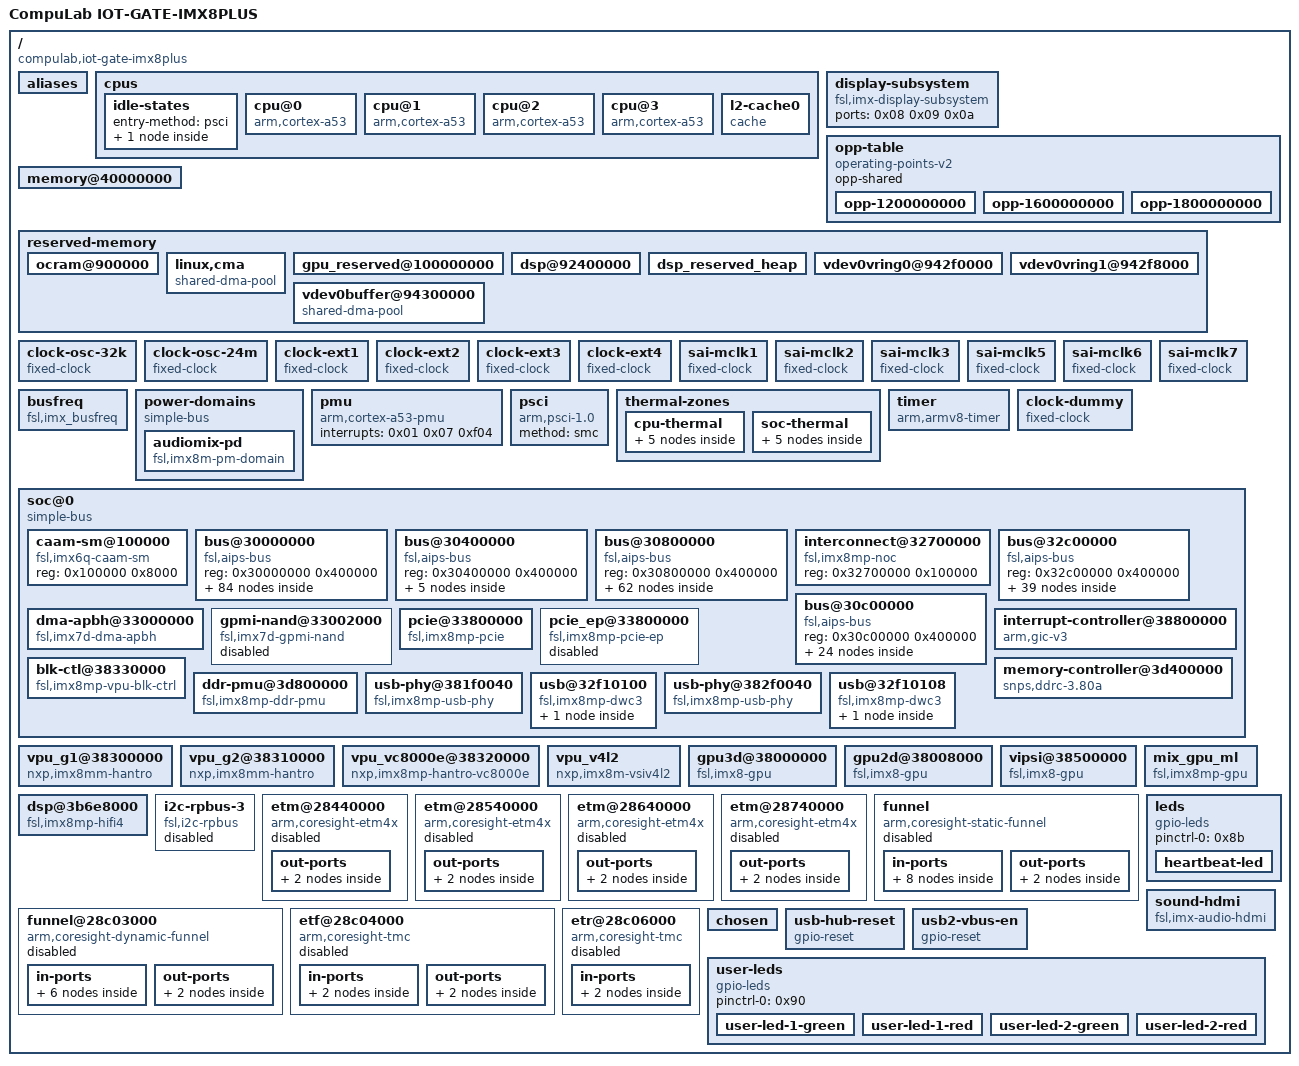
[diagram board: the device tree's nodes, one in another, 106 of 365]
/*
 * Copyright Linux Kernel Team
 *
 * SPDX-License-Identifier: GPL-2.0-only
 *
 * This file is derived from an intermediate build stage of the
 * Linux kernel. The licenses of all input files to this process
 * are compatible with GPL-2.0-only.
 */
/dts-v1/;

/ {
	interrupt-parent = <0x01>;
	#address-cells = <0x02>;
	#size-cells = <0x02>;
	model = "CompuLab IOT-GATE-IMX8PLUS";
	compatible = "compulab,iot-gate-imx8plus", "compulab,ucm-imx8m-plus-som", "fsl,imx8mp";

	aliases {
		ethernet0 = "/soc@0/bus@30800000/ethernet@30be0000";
		ethernet1 = "/soc@0/bus@30800000/ethernet@30bf0000";
		gpio0 = "/soc@0/bus@30000000/gpio@30200000";
		gpio1 = "/soc@0/bus@30000000/gpio@30210000";
		gpio2 = "/soc@0/bus@30000000/gpio@30220000";
		gpio3 = "/soc@0/bus@30000000/gpio@30230000";
		gpio4 = "/soc@0/bus@30000000/gpio@30240000";
		i2c0 = "/soc@0/bus@30800000/i2c@30a20000";
		i2c1 = "/soc@0/bus@30800000/i2c@30a30000";
		i2c2 = "/soc@0/bus@30800000/i2c@30a40000";
		i2c3 = "/soc@0/bus@30800000/i2c@30a50000";
		i2c4 = "/soc@0/bus@30800000/i2c@30ad0000";
		i2c5 = "/soc@0/bus@30800000/i2c@30ae0000";
		mmc0 = "/soc@0/bus@30800000/mmc@30b40000";
		mmc1 = "/soc@0/bus@30800000/mmc@30b50000";
		mmc2 = "/soc@0/bus@30800000/mmc@30b60000";
		serial0 = "/soc@0/bus@30800000/serial@30860000";
		serial1 = "/soc@0/bus@30800000/serial@30890000";
		serial2 = "/soc@0/bus@30800000/serial@30880000";
		serial3 = "/soc@0/bus@30800000/serial@30a60000";
		spi0 = "/soc@0/bus@30800000/spi@30bb0000";
		isi0 = "/soc@0/bus@32c00000/camera/isi@32e00000";
		isi1 = "/soc@0/bus@32c00000/camera/isi@32e02000";
		csi0 = "/soc@0/bus@32c00000/camera/csi@32e40000";
		csi1 = "/soc@0/bus@32c00000/camera/csi@32e50000";
		isp0 = "/soc@0/bus@32c00000/camera/isp@32e10000";
		isp1 = "/soc@0/bus@32c00000/camera/isp@32e20000";
		rtc0 = "/soc@0/bus@30800000/i2c@30a30000/rtc@69";
		rtc1 = "/soc@0/bus@30000000/snvs@30370000/snvs-rtc-lp";
	};

	cpus {
		#address-cells = <0x01>;
		#size-cells = <0x00>;

		idle-states {
			entry-method = "psci";

			cpu-pd-wait {
				compatible = "arm,idle-state";
				arm,psci-suspend-param = <0x10033>;
				local-timer-stop;
				entry-latency-us = <0x3e8>;
				exit-latency-us = <0x2bc>;
				min-residency-us = <0xa8c>;
				wakeup-latency-us = <0x5dc>;
				phandle = <0x06>;
			};
		};

		cpu@0 {
			device_type = "cpu";
			compatible = "arm,cortex-a53";
			reg = <0x00>;
			clock-latency = <0xee6c>;
			clocks = <0x02 0x11f>;
			enable-method = "psci";
			i-cache-size = <0x8000>;
			i-cache-line-size = <0x40>;
			i-cache-sets = <0x100>;
			d-cache-size = <0x8000>;
			d-cache-line-size = <0x40>;
			d-cache-sets = <0x80>;
			next-level-cache = <0x03>;
			nvmem-cells = <0x04>;
			nvmem-cell-names = "speed_grade";
			operating-points-v2 = <0x05>;
			#cooling-cells = <0x02>;
			cpu-idle-states = <0x06>;
			cpu-supply = <0x07>;
			phandle = <0x0d>;
		};

		cpu@1 {
			device_type = "cpu";
			compatible = "arm,cortex-a53";
			reg = <0x01>;
			clock-latency = <0xee6c>;
			clocks = <0x02 0x11f>;
			enable-method = "psci";
			i-cache-size = <0x8000>;
			i-cache-line-size = <0x40>;
			i-cache-sets = <0x100>;
			d-cache-size = <0x8000>;
			d-cache-line-size = <0x40>;
			d-cache-sets = <0x80>;
			next-level-cache = <0x03>;
			operating-points-v2 = <0x05>;
			#cooling-cells = <0x02>;
			cpu-idle-states = <0x06>;
			cpu-supply = <0x07>;
			phandle = <0x0e>;
		};

		cpu@2 {
			device_type = "cpu";
			compatible = "arm,cortex-a53";
			reg = <0x02>;
			clock-latency = <0xee6c>;
			clocks = <0x02 0x11f>;
			enable-method = "psci";
			i-cache-size = <0x8000>;
			i-cache-line-size = <0x40>;
			i-cache-sets = <0x100>;
			d-cache-size = <0x8000>;
			d-cache-line-size = <0x40>;
			d-cache-sets = <0x80>;
			next-level-cache = <0x03>;
			operating-points-v2 = <0x05>;
			#cooling-cells = <0x02>;
			cpu-idle-states = <0x06>;
			cpu-supply = <0x07>;
			phandle = <0x0f>;
		};

		cpu@3 {
			device_type = "cpu";
			compatible = "arm,cortex-a53";
			reg = <0x03>;
			clock-latency = <0xee6c>;
			clocks = <0x02 0x11f>;
			enable-method = "psci";
			i-cache-size = <0x8000>;
			i-cache-line-size = <0x40>;
			i-cache-sets = <0x100>;
			d-cache-size = <0x8000>;
			d-cache-line-size = <0x40>;
			d-cache-sets = <0x80>;
			next-level-cache = <0x03>;
			operating-points-v2 = <0x05>;
			#cooling-cells = <0x02>;
			cpu-idle-states = <0x06>;
			cpu-supply = <0x07>;
			phandle = <0x10>;
		};

		l2-cache0 {
			compatible = "cache";
			cache-level = <0x02>;
			cache-size = <0x80000>;
			cache-line-size = <0x40>;
			cache-sets = <0x200>;
			phandle = <0x03>;
		};
	};

	display-subsystem {
		compatible = "fsl,imx-display-subsystem";
		ports = <0x08 0x09 0x0a>;
	};

	opp-table {
		compatible = "operating-points-v2";
		opp-shared;
		phandle = <0x05>;

		opp-1200000000 {
			opp-hz = <0x00 0x47868c00>;
			opp-microvolt = <0xcf850>;
			opp-supported-hw = <0x8a0 0x07>;
			clock-latency-ns = <0x249f0>;
			opp-suspend;
		};

		opp-1600000000 {
			opp-hz = <0x00 0x5f5e1000>;
			opp-microvolt = <0xe7ef0>;
			opp-supported-hw = <0xa0 0x07>;
			clock-latency-ns = <0x249f0>;
			opp-suspend;
		};

		opp-1800000000 {
			opp-hz = <0x00 0x6b49d200>;
			opp-microvolt = <0xf4240>;
			opp-supported-hw = <0x20 0x03>;
			clock-latency-ns = <0x249f0>;
			opp-suspend;
		};
	};

	memory@40000000 {
		device_type = "memory";
		reg = <0x00 0x40000000 0x00 0xc0000000 0x01 0x00 0x00 0xc0000000>;
	};

	reserved-memory {
		#address-cells = <0x02>;
		#size-cells = <0x02>;
		ranges;
		phandle = <0x91>;

		ocram@900000 {
			no-map;
			reg = <0x00 0x900000 0x00 0x70000>;
			phandle = <0x92>;
		};

		linux,cma {
			compatible = "shared-dma-pool";
			reusable;
			size = <0x00 0x2c000000>;
			alloc-ranges = <0x00 0x40000000 0x00 0x80000000>;
			linux,cma-default;
		};

		gpu_reserved@100000000 {
			no-map;
			reg = <0x00 0x58000000 0x00 0x10000000>;
			phandle = <0x77>;
		};

		dsp@92400000 {
			reg = <0x00 0x92400000 0x00 0x1000000>;
			no-map;
			phandle = <0x7c>;
		};

		dsp_reserved_heap {
			reg = <0x00 0x93400000 0x00 0xef0000>;
			no-map;
			phandle = <0x93>;
		};

		vdev0vring0@942f0000 {
			reg = <0x00 0x942f0000 0x00 0x8000>;
			no-map;
			phandle = <0x7a>;
		};

		vdev0vring1@942f8000 {
			reg = <0x00 0x942f8000 0x00 0x8000>;
			no-map;
			phandle = <0x7b>;
		};

		vdev0buffer@94300000 {
			compatible = "shared-dma-pool";
			reg = <0x00 0x94300000 0x00 0x100000>;
			no-map;
			phandle = <0x79>;
		};
	};

	clock-osc-32k {
		compatible = "fixed-clock";
		#clock-cells = <0x00>;
		clock-frequency = <0x8000>;
		clock-output-names = "osc_32k";
		phandle = <0x17>;
	};

	clock-osc-24m {
		compatible = "fixed-clock";
		#clock-cells = <0x00>;
		clock-frequency = <0x16e3600>;
		clock-output-names = "osc_24m";
		phandle = <0x18>;
	};

	clock-ext1 {
		compatible = "fixed-clock";
		#clock-cells = <0x00>;
		clock-frequency = <0x7ed6b40>;
		clock-output-names = "clk_ext1";
		phandle = <0x19>;
	};

	clock-ext2 {
		compatible = "fixed-clock";
		#clock-cells = <0x00>;
		clock-frequency = <0x7ed6b40>;
		clock-output-names = "clk_ext2";
		phandle = <0x1a>;
	};

	clock-ext3 {
		compatible = "fixed-clock";
		#clock-cells = <0x00>;
		clock-frequency = <0x7ed6b40>;
		clock-output-names = "clk_ext3";
		phandle = <0x1b>;
	};

	clock-ext4 {
		compatible = "fixed-clock";
		#clock-cells = <0x00>;
		clock-frequency = <0x7ed6b40>;
		clock-output-names = "clk_ext4";
		phandle = <0x1c>;
	};

	sai-mclk1 {
		compatible = "fixed-clock";
		#clock-cells = <0x00>;
		clock-frequency = <0x00>;
		clock-output-names = "sai1_mclk";
		phandle = <0x94>;
	};

	sai-mclk2 {
		compatible = "fixed-clock";
		#clock-cells = <0x00>;
		clock-frequency = <0x00>;
		clock-output-names = "sai2_mclk";
		phandle = <0x95>;
	};

	sai-mclk3 {
		compatible = "fixed-clock";
		#clock-cells = <0x00>;
		clock-frequency = <0x00>;
		clock-output-names = "sai3_mclk";
		phandle = <0x96>;
	};

	sai-mclk5 {
		compatible = "fixed-clock";
		#clock-cells = <0x00>;
		clock-frequency = <0x00>;
		clock-output-names = "sai5_mclk";
		phandle = <0x97>;
	};

	sai-mclk6 {
		compatible = "fixed-clock";
		#clock-cells = <0x00>;
		clock-frequency = <0x00>;
		clock-output-names = "sai6_mclk";
		phandle = <0x98>;
	};

	sai-mclk7 {
		compatible = "fixed-clock";
		#clock-cells = <0x00>;
		clock-frequency = <0x00>;
		clock-output-names = "sai7_mclk";
		phandle = <0x99>;
	};

	busfreq {
		compatible = "fsl,imx_busfreq";
		clocks = <0x02 0x29 0x02 0x70 0x02 0x71 0x02 0x71 0x02 0x11e 0x02 0x11d 0x02 0x30 0x02 0x32 0x02 0x3f 0x02 0x67 0x02 0x6b 0x02 0x5d 0x02 0x02 0x02 0x38 0x02 0x15>;
		clock-names = "dram_pll", "dram_alt_src", "dram_apb_src", "dram_apb_pre_div", "dram_core", "dram_alt_root", "sys_pll1_40m", "sys_pll1_100m", "sys_pll2_333m", "noc_div", "ahb_div", "main_axi_src", "osc_24m", "sys_pll1_800m", "dram_pll_div";
	};

	power-domains {
		compatible = "simple-bus";

		audiomix-pd {
			compatible = "fsl,imx8m-pm-domain";
			#power-domain-cells = <0x00>;
			domain-index = <0x05>;
			domain-name = "audiomix";
			clocks = <0x02 0x141 0x02 0x142>;
			phandle = <0x60>;
		};
	};

	pmu {
		compatible = "arm,cortex-a53-pmu";
		interrupts = <0x01 0x07 0xf04>;
	};

	psci {
		compatible = "arm,psci-1.0";
		method = "smc";
	};

	thermal-zones {

		cpu-thermal {
			polling-delay-passive = <0xfa>;
			polling-delay = <0x7d0>;
			thermal-sensors = <0x0b 0x00>;

			trips {

				trip0 {
					temperature = <0x186a0>;
					hysteresis = <0x7d0>;
					type = "passive";
					phandle = <0x0c>;
				};

				trip1 {
					temperature = <0x19a28>;
					hysteresis = <0x7d0>;
					type = "critical";
					phandle = <0x9a>;
				};
			};

			cooling-maps {

				map0 {
					trip = <0x0c>;
					cooling-device = <0x0d 0xffffffff 0xffffffff 0x0e 0xffffffff 0xffffffff 0x0f 0xffffffff 0xffffffff 0x10 0xffffffff 0xffffffff>;
				};
			};
		};

		soc-thermal {
			polling-delay-passive = <0xfa>;
			polling-delay = <0x7d0>;
			thermal-sensors = <0x0b 0x01>;

			trips {

				trip0 {
					temperature = <0x186a0>;
					hysteresis = <0x7d0>;
					type = "passive";
					phandle = <0x11>;
				};

				trip1 {
					temperature = <0x19a28>;
					hysteresis = <0x7d0>;
					type = "critical";
					phandle = <0x9b>;
				};
			};

			cooling-maps {

				map0 {
					trip = <0x11>;
					cooling-device = <0x0d 0xffffffff 0xffffffff 0x0e 0xffffffff 0xffffffff 0x0f 0xffffffff 0xffffffff 0x10 0xffffffff 0xffffffff>;
				};
			};
		};
	};

	timer {
		compatible = "arm,armv8-timer";
		interrupts = <0x01 0x0d 0xf08 0x01 0x0e 0xf08 0x01 0x0b 0xf08 0x01 0x0a 0xf08>;
		clock-frequency = <0x7a1200>;
		arm,no-tick-in-suspend;
		interrupt-parent = <0x01>;
	};

	clock-dummy {
		compatible = "fixed-clock";
		#clock-cells = <0x00>;
		clock-frequency = <0x00>;
		clock-output-names = "clk_dummy";
		phandle = <0x9c>;
	};

	soc@0 {
		compatible = "simple-bus";
		#address-cells = <0x01>;
		#size-cells = <0x01>;
		ranges = <0x00 0x00 0x00 0x3e000000>;
		nvmem-cells = <0x12>;
		nvmem-cell-names = "soc_unique_id";
		phandle = <0x9d>;

		caam-sm@100000 {
			compatible = "fsl,imx6q-caam-sm";
			reg = <0x100000 0x8000>;
			phandle = <0x9e>;
		};

		bus@30000000 {
			compatible = "fsl,aips-bus", "simple-bus";
			reg = <0x30000000 0x400000>;
			#address-cells = <0x01>;
			#size-cells = <0x01>;
			ranges;
			phandle = <0x9f>;

			gpio@30200000 {
				compatible = "fsl,imx8mp-gpio", "fsl,imx35-gpio";
				reg = <0x30200000 0x10000>;
				interrupts = <0x00 0x40 0x04 0x00 0x41 0x04>;
				clocks = <0x02 0xc1>;
				gpio-controller;
				#gpio-cells = <0x02>;
				interrupt-controller;
				#interrupt-cells = <0x02>;
				gpio-ranges = <0x13 0x00 0x05 0x1e>;
				gpio-line-names = "", "", "", "PMIC IRQ", "", "", "", "", "", "", "ECOS PHY Reset", "", "Heartbeat LED", "", "", "USB MUX Sel", "", "", "", "", "", "", "", "", "", "", "", "", "", "";
				status = "okay";
				phandle = <0x2b>;
			};

			gpio@30210000 {
				compatible = "fsl,imx8mp-gpio", "fsl,imx35-gpio";
				reg = <0x30210000 0x10000>;
				interrupts = <0x00 0x42 0x04 0x00 0x43 0x04>;
				clocks = <0x02 0xc2>;
				gpio-controller;
				#gpio-cells = <0x02>;
				interrupt-controller;
				#interrupt-cells = <0x02>;
				gpio-ranges = <0x13 0x00 0x23 0x15>;
				phandle = <0x8e>;
			};

			gpio@30220000 {
				compatible = "fsl,imx8mp-gpio", "fsl,imx35-gpio";
				reg = <0x30220000 0x10000>;
				interrupts = <0x00 0x44 0x04 0x00 0x45 0x04>;
				clocks = <0x02 0xc3>;
				gpio-controller;
				#gpio-cells = <0x02>;
				interrupt-controller;
				#interrupt-cells = <0x02>;
				gpio-ranges = <0x13 0x00 0x38 0x1a 0x13 0x1a 0x90 0x04>;
				phandle = <0xa0>;
			};

			gpio@30230000 {
				compatible = "fsl,imx8mp-gpio", "fsl,imx35-gpio";
				reg = <0x30230000 0x10000>;
				interrupts = <0x00 0x46 0x04 0x00 0x47 0x04>;
				clocks = <0x02 0xc4>;
				gpio-controller;
				#gpio-cells = <0x02>;
				interrupt-controller;
				#interrupt-cells = <0x02>;
				gpio-ranges = <0x13 0x00 0x52 0x20>;
				phandle = <0x40>;
			};

			gpio@30240000 {
				compatible = "fsl,imx8mp-gpio", "fsl,imx35-gpio";
				reg = <0x30240000 0x10000>;
				interrupts = <0x00 0x48 0x04 0x00 0x49 0x04>;
				clocks = <0x02 0xc5>;
				gpio-controller;
				#gpio-cells = <0x02>;
				interrupt-controller;
				#interrupt-cells = <0x02>;
				gpio-ranges = <0x13 0x00 0x72 0x1e>;
				phandle = <0x22>;
			};

			tmu@30260000 {
				compatible = "fsl,imx8mp-tmu";
				reg = <0x30260000 0x10000>;
				clocks = <0x02 0x119>;
				#thermal-sensor-cells = <0x01>;
				phandle = <0x0b>;
			};

			watchdog@30280000 {
				compatible = "fsl,imx8mp-wdt", "fsl,imx21-wdt";
				reg = <0x30280000 0x10000>;
				interrupts = <0x00 0x4e 0x04>;
				clocks = <0x02 0x103>;
				status = "okay";
				pinctrl-names = "default";
				pinctrl-0 = <0x14>;
				fsl,ext-reset-output;
				phandle = <0xa1>;
			};

			watchdog@30290000 {
				compatible = "fsl,imx8mp-wdt", "fsl,imx21-wdt";
				reg = <0x30290000 0x10000>;
				interrupts = <0x00 0x4f 0x04>;
				clocks = <0x02 0x104>;
				status = "disabled";
				phandle = <0xa2>;
			};

			watchdog@302a0000 {
				compatible = "fsl,imx8mp-wdt", "fsl,imx21-wdt";
				reg = <0x302a0000 0x10000>;
				interrupts = <0x00 0x0a 0x04>;
				clocks = <0x02 0x105>;
				status = "disabled";
				phandle = <0xa3>;
			};

			pinctrl@30330000 {
				compatible = "fsl,imx8mp-iomuxc";
				reg = <0x30330000 0x10000>;
				pinctrl-names = "default";
				pinctrl-0 = <0x15>;
				phandle = <0x13>;

				fecgrp {
					fsl,pins = <0x8c 0x2ec 0x00 0x01 0x00 0x03 0x90 0x2f0 0x57c 0x01 0x00 0x03 0x9c 0x2fc 0x580 0x01 0x00 0x91 0xa0 0x300 0x584 0x01 0x00 0x91 0x168 0x3c8 0x00 0x04 0x00 0x91 0x16c 0x3cc 0x00 0x04 0x00 0x91 0x174 0x3d4 0x00 0x04 0x00 0x91 0x170 0x3d0 0x588 0x04 0x01 0x91 0x98 0x2f8 0x00 0x01 0x00 0x1f 0x94 0x2f4 0x00 0x01 0x00 0x1f 0x180 0x3e0 0x00 0x04 0x00 0x1f 0x184 0x3e4 0x00 0x04 0x00 0x1f 0x188 0x3e8 0x00 0x04 0x00 0x1f 0x18c 0x3ec 0x00 0x04 0x00 0x1f>;
					phandle = <0x3d>;
				};

				ecspi2grp {
					fsl,pins = <0x1f0 0x450 0x568 0x00 0x01 0x82 0x1f4 0x454 0x570 0x00 0x01 0x82 0x1f8 0x458 0x56c 0x00 0x01 0x82>;
					phandle = <0x20>;
				};

				ecspi2cs {
					fsl,pins = <0x1fc 0x45c 0x00 0x05 0x00 0x40000>;
					phandle = <0x21>;
				};

				eqosgrp {
					fsl,pins = <0x54 0x2b4 0x00 0x00 0x00 0x03 0x58 0x2b8 0x590 0x00 0x01 0x03 0x7c 0x2dc 0x00 0x00 0x00 0x91 0x80 0x2e0 0x00 0x00 0x00 0x91 0x84 0x2e4 0x00 0x00 0x00 0x91 0x88 0x2e8 0x00 0x00 0x00 0x91 0x78 0x2d8 0x00 0x00 0x00 0x91 0x74 0x2d4 0x00 0x00 0x00 0x91 0x68 0x2c8 0x00 0x00 0x00 0x1f 0x64 0x2c4 0x00 0x00 0x00 0x1f 0x60 0x2c0 0x00 0x00 0x00 0x1f 0x5c 0x2bc 0x00 0x00 0x00 0x1f 0x6c 0x2cc 0x00 0x00 0x00 0x1f 0x70 0x2d0 0x00 0x00 0x00 0x1f>;
					phandle = <0x42>;
				};

				ecosphyrstgrp {
					fsl,pins = <0x3c 0x29c 0x00 0x00 0x00 0x19>;
					phandle = <0x43>;
				};

				flexspi0grp {
					fsl,pins = <0xe0 0x340 0x00 0x01 0x00 0x1c2 0xe4 0x344 0x00 0x01 0x00 0x82 0xf8 0x358 0x00 0x01 0x00 0x82 0xfc 0x35c 0x00 0x01 0x00 0x82 0x100 0x360 0x00 0x01 0x00 0x82 0x104 0x364 0x00 0x01 0x00 0x82>;
					phandle = <0x3b>;
				};

				gpioledgrp {
					fsl,pins = <0x120 0x380 0x00 0x05 0x00 0x19>;
					phandle = <0x8b>;
				};

				i2c1grp {
					fsl,pins = <0x200 0x460 0x5a4 0x00 0x02 0x400001c3 0x204 0x464 0x5a8 0x00 0x02 0x400001c3>;
					phandle = <0x29>;
				};

				i2c2grp {
					fsl,pins = <0x208 0x468 0x5ac 0x00 0x02 0x400001c3 0x20c 0x46c 0x5b0 0x00 0x02 0x400001c3>;
					phandle = <0x2c>;
				};

				i2c3grp {
					fsl,pins = <0x210 0x470 0x5b4 0x00 0x04 0x400001c3 0x214 0x474 0x5b8 0x00 0x04 0x400001c3>;
					phandle = <0x2d>;
				};

				i2c5grp {
					fsl,pins = <0x144 0x3a4 0x5c8 0x03 0x01 0x400001c3 0x134 0x394 0x5c4 0x03 0x01 0x400001c3>;
					phandle = <0x30>;
				};

				i2c6grp {
					fsl,pins = <0x12c 0x38c 0x5cc 0x03 0x01 0x400001c3 0x130 0x390 0x5d0 0x03 0x01 0x400001c3>;
					phandle = <0x31>;
				};

				pmicirq {
					fsl,pins = <0x20 0x280 0x00 0x00 0x00 0x41>;
					phandle = <0x2a>;
				};

				pdmgrp {
					fsl,pins = <0x130 0x390 0x00 0x04 0x00 0xd6 0x134 0x394 0x4c0 0x04 0x03 0xd6 0x138 0x398 0x4c4 0x04 0x03 0xd6 0x13c 0x39c 0x4c8 0x04 0x03 0xd6 0x140 0x3a0 0x4cc 0x04 0x03 0xd6>;
					phandle = <0xa4>;
				};

				uart1grp {
					fsl,pins = <0x220 0x480 0x5e8 0x00 0x04 0x140 0x224 0x484 0x00 0x00 0x00 0x140>;
					phandle = <0x23>;
				};

				uart2grp {
					fsl,pins = <0x228 0x488 0x5f0 0x00 0x06 0x140 0x22c 0x48c 0x00 0x00 0x00 0x140>;
					phandle = <0x25>;
				};

				uart3grp {
					fsl,pins = <0x230 0x490 0x5f8 0x00 0x06 0x140 0x234 0x494 0x00 0x00 0x00 0x140>;
					phandle = <0x24>;
				};

				uart4grp {
					fsl,pins = <0x23c 0x49c 0x00 0x00 0x00 0x140 0x238 0x498 0x600 0x00 0x08 0x140>;
					phandle = <0x2e>;
				};

				usdhc1grp {
					fsl,pins = <0x8c 0x2ec 0x00 0x00 0x00 0x190 0x90 0x2f0 0x00 0x00 0x00 0x1d0 0x94 0x2f4 0x00 0x00 0x00 0x1d0 0x98 0x2f8 0x00 0x00 0x00 0x1d0 0x9c 0x2fc 0x00 0x00 0x00 0x1d0 0xa0 0x300 0x00 0x00 0x00 0x1d0>;
					phandle = <0x32>;
				};

				usdhc1grp-100mhz {
					fsl,pins = <0x8c 0x2ec 0x00 0x00 0x00 0x194 0x90 0x2f0 0x00 0x00 0x00 0x1d4 0x94 0x2f4 0x00 0x00 0x00 0x1d4 0x98 0x2f8 0x00 0x00 0x00 0x1d4 0x9c 0x2fc 0x00 0x00 0x00 0x1d4 0xa0 0x300 0x00 0x00 0x00 0x1d4>;
					phandle = <0x33>;
				};

				usdhc1grp-200mhz {
					fsl,pins = <0x8c 0x2ec 0x00 0x00 0x00 0x196 0x90 0x2f0 0x00 0x00 0x00 0x1d6 0x94 0x2f4 0x00 0x00 0x00 0x1d6 0x98 0x2f8 0x00 0x00 0x00 0x1d6 0x9c 0x2fc 0x00 0x00 0x00 0x1d6 0xa0 0x300 0x00 0x00 0x00 0x1d6>;
					phandle = <0x34>;
				};

				usdhc2grp {
					fsl,pins = <0xc0 0x320 0x00 0x00 0x00 0x190 0xc4 0x324 0x00 0x00 0x00 0x1d0 0xc8 0x328 0x00 0x00 0x00 0x1d0 0xcc 0x32c 0x00 0x00 0x00 0x1d0 0xd0 0x330 0x00 0x00 0x00 0x1d0 0xd4 0x334 0x00 0x00 0x00 0x1d0>;
					phandle = <0x35>;
				};

				usdhc2grp-100mhz {
					fsl,pins = <0xc0 0x320 0x00 0x00 0x00 0x194 0xc4 0x324 0x00 0x00 0x00 0x1d4 0xc8 0x328 0x00 0x00 0x00 0x1d4 0xcc 0x32c 0x00 0x00 0x00 0x1d4 0xd0 0x330 0x00 0x00 0x00 0x1d4 0xd4 0x334 0x00 0x00 0x00 0x1d4>;
					phandle = <0x36>;
				};

				usdhc2grp-200mhz {
					fsl,pins = <0xc0 0x320 0x00 0x00 0x00 0x196 0xc4 0x324 0x00 0x00 0x00 0x1d6 0xc8 0x328 0x00 0x00 0x00 0x1d6 0xcc 0x32c 0x00 0x00 0x00 0x1d6 0xd0 0x330 0x00 0x00 0x00 0x1d6 0xd4 0x334 0x00 0x00 0x00 0x1d6>;
					phandle = <0x37>;
				};

				usdhc3grp {
					fsl,pins = <0x124 0x384 0x604 0x02 0x01 0x190 0x128 0x388 0x60c 0x02 0x01 0x1d0 0x108 0x368 0x610 0x02 0x01 0x1d0 0x10c 0x36c 0x614 0x02 0x01 0x1d0 0x110 0x370 0x618 0x02 0x01 0x1d0 0x114 0x374 0x61c 0x02 0x01 0x1d0 0x11c 0x37c 0x620 0x02 0x01 0x1d0 0xec 0x34c 0x624 0x02 0x01 0x1d0 0xf0 0x350 0x628 0x02 0x01 0x1d0 0xf4 0x354 0x62c 0x02 0x01 0x1d0 0xe8 0x348 0x630 0x02 0x01 0x190>;
					phandle = <0x38>;
				};

				usdhc3grp-100mhz {
					fsl,pins = <0x124 0x384 0x604 0x02 0x01 0x194 0x128 0x388 0x60c 0x02 0x01 0x1d4 0x108 0x368 0x610 0x02 0x01 0x1d4 0x10c 0x36c 0x614 0x02 0x01 0x1d4 0x110 0x370 0x618 0x02 0x01 0x1d4 0x114 0x374 0x61c 0x02 0x01 0x1d4 0x11c 0x37c 0x620 0x02 0x01 0x1d4 0xec 0x34c 0x624 0x02 0x01 0x1d4 0xf0 0x350 0x628 0x02 0x01 0x1d4 0xf4 0x354 0x62c 0x02 0x01 0x1d4 0xe8 0x348 0x630 0x02 0x01 0x194>;
					phandle = <0x39>;
				};

				usdhc3grp-200mhz {
					fsl,pins = <0x124 0x384 0x604 0x02 0x01 0x196 0x128 0x388 0x60c 0x02 0x01 0x1d6 0x108 0x368 0x610 0x02 0x01 0x1d6 0x10c 0x36c 0x614 0x02 0x01 0x1d6 0x110 0x370 0x618 0x02 0x01 0x1d6 0x114 0x374 0x61c 0x02 0x01 0x1d6 0x11c 0x37c 0x620 0x02 0x01 0x1d6 0xec 0x34c 0x624 0x02 0x01 0x1d6 0xf0 0x350 0x628 0x02 0x01 0x1d6 0xf4 0x354 0x62c 0x02 0x01 0x1d6 0xe8 0x348 0x630 0x02 0x01 0x196>;
					phandle = <0x3a>;
				};

				wdoggrp {
					fsl,pins = <0x1c 0x27c 0x00 0x01 0x00 0xc6>;
					phandle = <0x14>;
				};

				flexcan1grp {
					fsl,pins = <0x1a0 0x400 0x00 0x03 0x00 0x154 0x1ac 0x40c 0x54c 0x03 0x01 0x154>;
					phandle = <0x27>;
				};

				flexcan2grp {
					fsl,pins = <0x1b0 0x410 0x00 0x03 0x00 0x154 0x1b4 0x414 0x550 0x03 0x01 0x154>;
					phandle = <0x28>;
				};

				hdmigrp {
					fsl,pins = <0x240 0x4a0 0x00 0x00 0x00 0x400001c3 0x244 0x4a4 0x00 0x00 0x00 0x400001c3 0x24c 0x4ac 0x00 0x00 0x00 0x40000019 0x248 0x4a8 0x00 0x00 0x00 0x40000019>;
					phandle = <0x65>;
				};

				fecphyrstgrp {
					fsl,pins = <0x1a8 0x408 0x00 0x05 0x00 0x19>;
					phandle = <0x3e>;
				};

				iedi4o4grp {
					fsl,pins = <0x1d4 0x434 0x00 0x05 0x00 0x00 0x1c8 0x428 0x00 0x05 0x00 0x00 0x1c4 0x424 0x00 0x05 0x00 0x00 0x1bc 0x41c 0x00 0x05 0x00 0x00 0x1c0 0x420 0x00 0x05 0x00 0x100 0x1d8 0x438 0x00 0x05 0x00 0x100 0x18 0x278 0x00 0x00 0x00 0x100 0x178 0x3d8 0x00 0x05 0x00 0x100>;
					phandle = <0x15>;
				};

				pciegrp {
					fsl,pins = <0x1d0 0x430 0x00 0x05 0x00 0x41>;
					phandle = <0x69>;
				};

				usbhubrst {
					fsl,pins = <0xb4 0x314 0x00 0x05 0x00 0x19>;
					phandle = <0x8d>;
				};

				usbmuxselgrp {
					fsl,pins = <0x50 0x2b0 0x00 0x00 0x00 0x114>;
					phandle = <0x6f>;
				};

				usb2vbusengrp {
					fsl,pins = <0x198 0x3f8 0x00 0x05 0x00 0x154>;
					phandle = <0x8f>;
				};

				userledsgrp {
					fsl,pins = <0xbc 0x31c 0x00 0x05 0x00 0x19 0x1dc 0x43c 0x00 0x05 0x00 0x19 0x1cc 0x42c 0x00 0x05 0x00 0x19 0x1b8 0x418 0x00 0x05 0x00 0x19>;
					phandle = <0x90>;
				};
			};

			iomuxc-gpr@30340000 {
				compatible = "fsl,imx8mp-iomuxc-gpr", "syscon";
				reg = <0x30340000 0x10000>;
				phandle = <0x26>;
			};

			efuse@30350000 {
				compatible = "fsl,imx8mp-ocotp", "fsl,imx8mm-ocotp", "syscon", "simple-mfd";
				reg = <0x30350000 0x10000>;
				clocks = <0x02 0xd6>;
				#address-cells = <0x01>;
				#size-cells = <0x01>;
				phandle = <0xa5>;

				unique-id@8 {
					reg = <0x08 0x08>;
					phandle = <0x12>;
				};

				speed-grade@10 {
					reg = <0x10 0x04>;
					phandle = <0x04>;
				};

				mac-address@90 {
					reg = <0x90 0x06>;
					phandle = <0x3c>;
				};

				mac-address@96 {
					reg = <0x96 0x06>;
					phandle = <0x41>;
				};

				imx8mp-soc {
					compatible = "fsl,imx8mp-soc";
					nvmem-cells = <0x12>;
					nvmem-cell-names = "soc_unique_id";
					phandle = <0xa6>;
				};
			};

			anatop@30360000 {
				compatible = "fsl,imx8mp-anatop", "fsl,imx8mm-anatop", "syscon";
				reg = <0x30360000 0x10000>;
				phandle = <0xa7>;
			};

			caam_secvio {
				compatible = "fsl,imx6q-caam-secvio";
				interrupts = <0x00 0x14 0x04>;
				jtag-tamper = "disabled";
				watchdog-tamper = "enabled";
				internal-boot-tamper = "enabled";
				external-pin-tamper = "disabled";
				phandle = <0xa8>;
			};

			caam-snvs@30370000 {
				compatible = "fsl,imx6q-caam-snvs";
				reg = <0x30370000 0x10000>;
				clocks = <0x02 0xf9>;
				clock-names = "ipg";
				phandle = <0xa9>;
			};

			snvs@30370000 {
				compatible = "fsl,sec-v4.0-mon", "syscon", "simple-mfd";
				reg = <0x30370000 0x10000>;
				phandle = <0x16>;

				snvs-rtc-lp {
					compatible = "fsl,sec-v4.0-mon-rtc-lp";
					regmap = <0x16>;
					offset = <0x34>;
					interrupts = <0x00 0x13 0x04 0x00 0x14 0x04>;
					clocks = <0x02 0xf9>;
					clock-names = "snvs-rtc";
					phandle = <0xaa>;
				};

				snvs-powerkey {
					compatible = "fsl,sec-v4.0-pwrkey";
					regmap = <0x16>;
					interrupts = <0x00 0x04 0x04>;
					clocks = <0x02 0xf9>;
					clock-names = "snvs-pwrkey";
					linux,keycode = <0x74>;
					wakeup-source;
					status = "okay";
					phandle = <0xab>;
				};

				snvs-lpgpr {
					compatible = "fsl,imx8mp-snvs-lpgpr", "fsl,imx7d-snvs-lpgpr";
					phandle = <0xac>;
				};
			};

			clock-controller@30380000 {
				compatible = "fsl,imx8mp-ccm";
				reg = <0x30380000 0x10000>;
				#clock-cells = <0x01>;
				clocks = <0x17 0x18 0x19 0x1a 0x1b 0x1c>;
				clock-names = "osc_32k", "osc_24m", "clk_ext1", "clk_ext2", "clk_ext3", "clk_ext4";
				assigned-clocks = <0x02 0x42 0x02 0x120 0x02 0x67 0x02 0x68 0x02 0x94 0x02 0x6c 0x02 0x48 0x02 0x12 0x02 0x13 0x02 0x14>;
				assigned-clock-parents = <0x02 0x38 0x02 0x2c 0x02 0x41 0x02 0x38 0x02 0x40 0x02 0x38 0x02 0x38>;
				assigned-clock-rates = <0x00 0x00 0x3b9aca00 0x2faf0800 0x1dcd6500 0x17d78400 0x2faf0800 0x17700000 0x15888000 0x3df582e0>;
				phandle = <0x02>;
			};

			reset-controller@30390000 {
				compatible = "fsl,imx8mp-src", "syscon";
				reg = <0x30390000 0x10000>;
				interrupts = <0x00 0x59 0x04>;
				#reset-cells = <0x01>;
				phandle = <0x50>;
			};

			gpc@303a0000 {
				compatible = "fsl,imx8mp-gpc";
				reg = <0x303a0000 0x1000>;
				interrupt-parent = <0x01>;
				interrupts = <0x00 0x57 0x04>;
				interrupt-controller;
				#interrupt-cells = <0x03>;
				phandle = <0xad>;

				pgc {
					#address-cells = <0x01>;
					#size-cells = <0x00>;

					power-domain@0 {
						#power-domain-cells = <0x00>;
						reg = <0x00>;
						phandle = <0x4d>;
					};

					power-domain@1 {
						#power-domain-cells = <0x00>;
						reg = <0x01>;
						phandle = <0x55>;
					};

					power-domain@2 {
						#power-domain-cells = <0x00>;
						reg = <0x02>;
						phandle = <0x53>;
					};

					power-domain@3 {
						#power-domain-cells = <0x00>;
						reg = <0x03>;
						phandle = <0x54>;
					};

					power-domain@7 {
						#power-domain-cells = <0x00>;
						reg = <0x07>;
						clocks = <0x02 0x107 0x02 0x65 0x02 0x66>;
						assigned-clocks = <0x02 0x65 0x02 0x66>;
						assigned-clock-parents = <0x02 0x38 0x02 0x38>;
						assigned-clock-rates = <0x2faf0800 0x17d78400>;
						phandle = <0x1d>;
					};

					power-domain@6 {
						#power-domain-cells = <0x00>;
						reg = <0x06>;
						clocks = <0x02 0xf7>;
						power-domains = <0x1d>;
						phandle = <0x72>;
					};

					power-domain@9 {
						#power-domain-cells = <0x00>;
						reg = <0x09>;
						clocks = <0x02 0xf8 0x02 0x134>;
						power-domains = <0x1d>;
						phandle = <0x71>;
					};

					power-domain@10 {
						#power-domain-cells = <0x00>;
						reg = <0x0a>;
						clocks = <0x02 0x10e 0x02 0x10d>;
						phandle = <0x4c>;
					};

					power-domains@14 {
						#power-domain-cells = <0x00>;
						reg = <0x0e>;
						clocks = <0x02 0x116 0x02 0x63>;
						assigned-clocks = <0x02 0x64 0x02 0x63>;
						assigned-clock-parents = <0x02 0x40 0x02 0x33>;
						assigned-clock-rates = <0x1dcd6500 0x7ed6b40>;
						phandle = <0x56>;
					};

					power-domains@15 {
						#power-domain-cells = <0x00>;
						reg = <0x0f>;
						phandle = <0x57>;
					};

					power-domain@16 {
						#power-domain-cells = <0x00>;
						reg = <0x10>;
						phandle = <0x4e>;
					};

					power-domain@17 {
						#power-domain-cells = <0x00>;
						reg = <0x11>;
						clocks = <0x02 0x137 0x02 0x10c>;
						assigned-clocks = <0x02 0x137>;
						assigned-clock-parents = <0x02 0x40>;
						assigned-clock-rates = <0x1dcd6500>;
						phandle = <0x52>;
					};

					power-domain@18 {
						#power-domain-cells = <0x00>;
						reg = <0x12>;
						clocks = <0x02 0x114>;
						phandle = <0x4f>;
					};

					power-domain@19 {
						#power-domain-cells = <0x00>;
						reg = <0x08>;
						clocks = <0x02 0x11a>;
						phandle = <0x1e>;
					};

					power-domain@20 {
						#power-domain-cells = <0x00>;
						power-domains = <0x1e>;
						reg = <0x0b>;
						clocks = <0x02 0x106>;
						phandle = <0x6a>;
					};

					power-domain@21 {
						#power-domain-cells = <0x00>;
						power-domains = <0x1e>;
						reg = <0x0c>;
						clocks = <0x02 0x10a>;
						phandle = <0x6b>;
					};

					power-domain@22 {
						#power-domain-cells = <0x00>;
						power-domains = <0x1e>;
						reg = <0x0d>;
						clocks = <0x02 0x109>;
						phandle = <0x6c>;
					};

					power-domain@24 {
						#power-domain-cells = <0x00>;
						reg = <0x04>;
						clocks = <0x02 0x69 0x02 0x6a 0x02 0x10b>;
						phandle = <0x73>;
					};
				};
			};
		};

		bus@30400000 {
			compatible = "fsl,aips-bus", "simple-bus";
			reg = <0x30400000 0x400000>;
			#address-cells = <0x01>;
			#size-cells = <0x01>;
			ranges;
			phandle = <0xae>;

			pwm@30660000 {
				compatible = "fsl,imx8mp-pwm", "fsl,imx27-pwm";
				reg = <0x30660000 0x10000>;
				interrupts = <0x00 0x51 0x04>;
				clocks = <0x02 0xdc 0x02 0xdc>;
				clock-names = "ipg", "per";
				#pwm-cells = <0x03>;
				status = "disabled";
				phandle = <0xaf>;
			};

			pwm@30670000 {
				compatible = "fsl,imx8mp-pwm", "fsl,imx27-pwm";
				reg = <0x30670000 0x10000>;
				interrupts = <0x00 0x52 0x04>;
				clocks = <0x02 0xdd 0x02 0xdd>;
				clock-names = "ipg", "per";
				#pwm-cells = <0x03>;
				status = "disabled";
				phandle = <0xb0>;
			};

			pwm@30680000 {
				compatible = "fsl,imx8mp-pwm", "fsl,imx27-pwm";
				reg = <0x30680000 0x10000>;
				interrupts = <0x00 0x53 0x04>;
				clocks = <0x02 0xde 0x02 0xde>;
				clock-names = "ipg", "per";
				#pwm-cells = <0x03>;
				status = "disabled";
				phandle = <0xb1>;
			};

			pwm@30690000 {
				compatible = "fsl,imx8mp-pwm", "fsl,imx27-pwm";
				reg = <0x30690000 0x10000>;
				interrupts = <0x00 0x54 0x04>;
				clocks = <0x02 0xdf 0x02 0xdf>;
				clock-names = "ipg", "per";
				#pwm-cells = <0x03>;
				status = "disabled";
				phandle = <0xb2>;
			};

			timer@306a0000 {
				compatible = "nxp,sysctr-timer";
				reg = <0x306a0000 0x20000>;
				interrupts = <0x00 0x2f 0x04>;
				clocks = <0x18>;
				clock-names = "per";
				phandle = <0xb3>;
			};
		};

		bus@30800000 {
			compatible = "fsl,aips-bus", "simple-bus";
			reg = <0x30800000 0x400000>;
			#address-cells = <0x01>;
			#size-cells = <0x01>;
			ranges;
			phandle = <0xb4>;

			spi@30820000 {
				#address-cells = <0x01>;
				#size-cells = <0x00>;
				compatible = "fsl,imx8mp-ecspi", "fsl,imx6ul-ecspi";
				reg = <0x30820000 0x10000>;
				interrupts = <0x00 0x1f 0x04>;
				clocks = <0x02 0xbd 0x02 0xbd>;
				clock-names = "ipg", "per";
				assigned-clock-rates = <0x4c4b400>;
				assigned-clocks = <0x02 0x95>;
				assigned-clock-parents = <0x02 0x38>;
				dmas = <0x1f 0x00 0x07 0x01 0x1f 0x01 0x07 0x02>;
				dma-names = "rx", "tx";
				status = "disabled";
				phandle = <0xb5>;
			};

			spi@30830000 {
				#address-cells = <0x01>;
				#size-cells = <0x00>;
				compatible = "fsl,imx8mp-ecspi", "fsl,imx6ul-ecspi";
				reg = <0x30830000 0x10000>;
				interrupts = <0x00 0x20 0x04>;
				clocks = <0x02 0xbe 0x02 0xbe>;
				clock-names = "ipg", "per";
				assigned-clock-rates = <0x4c4b400>;
				assigned-clocks = <0x02 0x96>;
				assigned-clock-parents = <0x02 0x38>;
				dmas = <0x1f 0x02 0x07 0x01 0x1f 0x03 0x07 0x02>;
				dma-names = "rx", "tx";
				status = "okay";
				fsl,spi-num-chipselects = <0x01>;
				pinctrl-names = "default";
				pinctrl-0 = <0x20 0x21>;
				cs-gpios = <0x22 0x0d 0x01>;
				phandle = <0xb6>;

				spidev2@0 {
					reg = <0x00>;
					compatible = "rohm,dh2228fv";
					spi-max-frequency = <0x7a120>;
					status = "okay";
					phandle = <0xb7>;
				};
			};

			spi@30840000 {
				#address-cells = <0x01>;
				#size-cells = <0x00>;
				compatible = "fsl,imx8mp-ecspi", "fsl,imx6ul-ecspi";
				reg = <0x30840000 0x10000>;
				interrupts = <0x00 0x21 0x04>;
				clocks = <0x02 0xbf 0x02 0xbf>;
				clock-names = "ipg", "per";
				assigned-clock-rates = <0x4c4b400>;
				assigned-clocks = <0x02 0xb3>;
				assigned-clock-parents = <0x02 0x38>;
				dmas = <0x1f 0x04 0x07 0x01 0x1f 0x05 0x07 0x02>;
				dma-names = "rx", "tx";
				status = "disabled";
				phandle = <0xb8>;
			};

			serial@30860000 {
				compatible = "fsl,imx8mp-uart", "fsl,imx6q-uart";
				reg = <0x30860000 0x10000>;
				interrupts = <0x00 0x1a 0x04>;
				clocks = <0x02 0xfb 0x02 0xfb>;
				clock-names = "ipg", "per";
				dmas = <0x1f 0x16 0x04 0x00 0x1f 0x17 0x04 0x00>;
				dma-names = "rx", "tx";
				status = "okay";
				pinctrl-names = "default";
				pinctrl-0 = <0x23>;
				assigned-clocks = <0x02 0x8e>;
				assigned-clock-parents = <0x02 0x31>;
				phandle = <0xb9>;
			};

			serial@30880000 {
				compatible = "fsl,imx8mp-uart", "fsl,imx6q-uart";
				reg = <0x30880000 0x10000>;
				interrupts = <0x00 0x1c 0x04>;
				clocks = <0x02 0xfd 0x02 0xfd>;
				clock-names = "ipg", "per";
				dmas = <0x1f 0x1a 0x04 0x00 0x1f 0x1b 0x04 0x00>;
				dma-names = "rx", "tx";
				status = "okay";
				pinctrl-names = "default";
				pinctrl-0 = <0x24>;
				assigned-clocks = <0x02 0x90>;
				assigned-clock-parents = <0x02 0x31>;
				phandle = <0xba>;
			};

			serial@30890000 {
				compatible = "fsl,imx8mp-uart", "fsl,imx6q-uart";
				reg = <0x30890000 0x10000>;
				interrupts = <0x00 0x1b 0x04>;
				clocks = <0x02 0xfc 0x02 0xfc>;
				clock-names = "ipg", "per";
				dmas = <0x1f 0x18 0x04 0x00 0x1f 0x19 0x04 0x00>;
				dma-names = "rx", "tx";
				status = "okay";
				pinctrl-names = "default";
				pinctrl-0 = <0x25>;
				phandle = <0xbb>;
			};

			can@308c0000 {
				compatible = "fsl,imx8mp-flexcan";
				reg = <0x308c0000 0x10000>;
				interrupts = <0x00 0x8e 0x04>;
				clocks = <0x02 0x6e 0x02 0xe9>;
				clock-names = "ipg", "per";
				assigned-clocks = <0x02 0x74>;
				assigned-clock-parents = <0x02 0x30>;
				assigned-clock-rates = <0x2625a00>;
				fsl,clk-source = [00];
				fsl,stop-mode = <0x26 0x10 0x04>;
				status = "okay";
				pinctrl-names = "default";
				pinctrl-0 = <0x27>;
				phandle = <0xbc>;
			};

			can@308d0000 {
				compatible = "fsl,imx8mp-flexcan";
				reg = <0x308d0000 0x10000>;
				interrupts = <0x00 0x90 0x04>;
				clocks = <0x02 0x6e 0x02 0xea>;
				clock-names = "ipg", "per";
				assigned-clocks = <0x02 0x75>;
				assigned-clock-parents = <0x02 0x30>;
				assigned-clock-rates = <0x2625a00>;
				fsl,clk-source = [00];
				fsl,stop-mode = <0x26 0x10 0x05>;
				status = "okay";
				pinctrl-names = "default";
				pinctrl-0 = <0x28>;
				phandle = <0xbd>;
			};

			crypto@30900000 {
				compatible = "fsl,sec-v4.0";
				#address-cells = <0x01>;
				#size-cells = <0x01>;
				reg = <0x30900000 0x40000>;
				ranges = <0x00 0x30900000 0x40000>;
				interrupts = <0x00 0x5b 0x04>;
				clocks = <0x02 0x6b 0x02 0x6e>;
				clock-names = "aclk", "ipg";
				phandle = <0xbe>;

				jr@1000 {
					compatible = "fsl,sec-v4.0-job-ring";
					reg = <0x1000 0x1000>;
					interrupts = <0x00 0x69 0x04>;
					status = "disabled";
					phandle = <0xbf>;
				};

				jr@2000 {
					compatible = "fsl,sec-v4.0-job-ring";
					reg = <0x2000 0x1000>;
					interrupts = <0x00 0x6a 0x04>;
					phandle = <0xc0>;
				};

				jr@3000 {
					compatible = "fsl,sec-v4.0-job-ring";
					reg = <0x3000 0x1000>;
					interrupts = <0x00 0x72 0x04>;
					phandle = <0xc1>;
				};
			};

			i2c@30a20000 {
				compatible = "fsl,imx8mp-i2c", "fsl,imx21-i2c";
				#address-cells = <0x01>;
				#size-cells = <0x00>;
				reg = <0x30a20000 0x10000>;
				interrupts = <0x00 0x23 0x04>;
				clocks = <0x02 0xcd>;
				status = "okay";
				clock-frequency = <0x186a0>;
				pinctrl-names = "default";
				pinctrl-0 = <0x29>;
				phandle = <0xc2>;

				pca9450@25 {
					reg = <0x25>;
					compatible = "nxp,pca9450c";
					pinctrl-0 = <0x2a>;
					interrupt-parent = <0x2b>;
					interrupts = <0x03 0x01>;
					phandle = <0xc3>;

					regulators {

						BUCK1 {
							regulator-name = "BUCK1";
							regulator-min-microvolt = <0x927c0>;
							regulator-max-microvolt = <0x2160ec>;
							regulator-boot-on;
							regulator-always-on;
							regulator-ramp-delay = <0xc35>;
							phandle = <0xc4>;
						};

						BUCK2 {
							regulator-name = "BUCK2";
							regulator-min-microvolt = <0x927c0>;
							regulator-max-microvolt = <0x2160ec>;
							regulator-boot-on;
							regulator-always-on;
							regulator-ramp-delay = <0xc35>;
							nxp,dvs-run-voltage = <0xe7ef0>;
							nxp,dvs-standby-voltage = <0xcf850>;
							phandle = <0x07>;
						};

						BUCK4 {
							regulator-name = "BUCK4";
							regulator-min-microvolt = <0x927c0>;
							regulator-max-microvolt = <0x33e140>;
							regulator-boot-on;
							regulator-always-on;
							phandle = <0xc5>;
						};

						BUCK5 {
							regulator-name = "BUCK5";
							regulator-min-microvolt = <0x927c0>;
							regulator-max-microvolt = <0x33e140>;
							regulator-boot-on;
							regulator-always-on;
							phandle = <0xc6>;
						};

						BUCK6 {
							regulator-name = "BUCK6";
							regulator-min-microvolt = <0x927c0>;
							regulator-max-microvolt = <0x33e140>;
							regulator-boot-on;
							regulator-always-on;
							phandle = <0xc7>;
						};

						LDO1 {
							regulator-name = "LDO1";
							regulator-min-microvolt = <0x186a00>;
							regulator-max-microvolt = <0x325aa0>;
							regulator-boot-on;
							regulator-always-on;
							phandle = <0xc8>;
						};

						LDO2 {
							regulator-name = "LDO2";
							regulator-min-microvolt = "", "\f5";
							regulator-max-microvolt = <0x118c30>;
							regulator-boot-on;
							regulator-always-on;
							phandle = <0xc9>;
						};

						LDO3 {
							regulator-name = "LDO3";
							regulator-min-microvolt = "", "\f5";
							regulator-max-microvolt = <0x325aa0>;
							regulator-boot-on;
							regulator-always-on;
							phandle = <0xca>;
						};

						LDO4 {
							regulator-name = "LDO4";
							regulator-min-microvolt = "", "\f5";
							regulator-max-microvolt = <0x325aa0>;
							regulator-boot-on;
							regulator-always-on;
							phandle = <0xcb>;
						};

						LDO5 {
							regulator-name = "LDO5";
							regulator-min-microvolt = <0x1b7740>;
							regulator-max-microvolt = <0x325aa0>;
							regulator-boot-on;
							regulator-always-on;
							phandle = <0xcc>;
						};
					};
				};
			};

			i2c@30a30000 {
				compatible = "fsl,imx8mp-i2c", "fsl,imx21-i2c";
				#address-cells = <0x01>;
				#size-cells = <0x00>;
				reg = <0x30a30000 0x10000>;
				interrupts = <0x00 0x24 0x04>;
				clocks = <0x02 0xce>;
				status = "okay";
				clock-frequency = <0x61a80>;
				pinctrl-names = "default";
				pinctrl-0 = <0x2c>;
				phandle = <0xcd>;

				eeprom@50 {
					compatible = "atmel,24c08";
					reg = <0x50>;
					pagesize = <0x10>;
				};

				rtc@69 {
					compatible = "ab1805";
					reg = <0x69>;
					pagesize = <0x10>;
					sqw = "32768_Hz";
					xt-frequency = <0x1f410cc>;
					status = "okay";
					phandle = <0xce>;
				};

				eeprom@54 {
					compatible = "atmel,24c08";
					reg = <0x54>;
					pagesize = <0x10>;
				};
			};

			i2c@30a40000 {
				compatible = "fsl,imx8mp-i2c", "fsl,imx21-i2c";
				#address-cells = <0x01>;
				#size-cells = <0x00>;
				reg = <0x30a40000 0x10000>;
				interrupts = <0x00 0x25 0x04>;
				clocks = <0x02 0xcf>;
				status = "okay";
				clock-frequency = <0x186a0>;
				pinctrl-names = "default";
				pinctrl-0 = <0x2d>;
				phandle = <0xcf>;

				pca9555-sb@21 {
					compatible = "nxp,pca9555";
					gpio-controller;
					#gpio-cells = <0x02>;
					reg = <0x21>;
					gpio-line-names = "POD1_DET1", "POD1_DET2", "POD1_DET3", "POD2_DET1", "POD2_DET2", "POD2_DET3", "POD3_DET1", "POD3_DET2", "POD3_DET3", "POD4_DET1", "POD4_DET2", "POD4_DET3", "GPIO_IE_A", "GPIO_IE_B", "GPIO_IE_C", "RF_KILL#";
					phandle = <0xd0>;
				};
			};

			i2c@30a50000 {
				compatible = "fsl,imx8mp-i2c", "fsl,imx21-i2c";
				#address-cells = <0x01>;
				#size-cells = <0x00>;
				reg = <0x30a50000 0x10000>;
				interrupts = <0x00 0x26 0x04>;
				clocks = <0x02 0xd0>;
				status = "disabled";
				phandle = <0xd1>;
			};

			serial@30a60000 {
				compatible = "fsl,imx8mp-uart", "fsl,imx6q-uart";
				reg = <0x30a60000 0x10000>;
				interrupts = <0x00 0x1d 0x04>;
				clocks = <0x02 0xfe 0x02 0xfe>;
				clock-names = "ipg", "per";
				dmas = <0x1f 0x1c 0x04 0x00 0x1f 0x1d 0x04 0x00>;
				dma-names = "rx", "tx";
				status = "okay";
				pinctrl-names = "default";
				pinctrl-0 = <0x2e>;
				assigned-clocks = <0x02 0x91>;
				assigned-clock-parents = <0x02 0x31>;
				phandle = <0xd2>;
			};

			mailbox@30aa0000 {
				compatible = "fsl,imx8mp-mu", "fsl,imx6sx-mu";
				reg = <0x30aa0000 0x10000>;
				interrupts = <0x00 0x58 0x04>;
				clocks = <0x02 0xd5>;
				#mbox-cells = <0x02>;
				phandle = <0xd3>;
			};

			mailbox@30e60000 {
				compatible = "fsl,imx8-mu-dsp", "fsl,imx6sx-mu";
				reg = <0x30e60000 0x10000>;
				interrupts = <0x00 0x88 0x04>;
				fsl,dsp_ap_mu_id = <0x02>;
				#mbox-cells = <0x02>;
				clocks = <0x2f 0x24>;
				status = "okay";
				phandle = <0x78>;
			};

			i2c@30ad0000 {
				compatible = "fsl,imx8mp-i2c", "fsl,imx21-i2c";
				#address-cells = <0x01>;
				#size-cells = <0x00>;
				reg = <0x30ad0000 0x10000>;
				interrupts = <0x00 0x4c 0x04>;
				clocks = <0x02 0xe7>;
				status = "okay";
				clock-frequency = <0x61a80>;
				pinctrl-names = "default";
				pinctrl-0 = <0x30>;
				phandle = <0xd4>;
			};

			i2c@30ae0000 {
				compatible = "fsl,imx8mp-i2c", "fsl,imx21-i2c";
				#address-cells = <0x01>;
				#size-cells = <0x00>;
				reg = <0x30ae0000 0x10000>;
				interrupts = <0x00 0x4d 0x04>;
				clocks = <0x02 0xe8>;
				status = "okay";
				clock-frequency = <0x61a80>;
				pinctrl-names = "default";
				pinctrl-0 = <0x31>;
				phandle = <0xd5>;
			};

			mmc@30b40000 {
				compatible = "fsl,imx8mp-usdhc", "fsl,imx8mm-usdhc", "fsl,imx7d-usdhc";
				reg = <0x30b40000 0x10000>;
				interrupts = <0x00 0x16 0x04>;
				clocks = <0x02 0x00 0x02 0x5f 0x02 0x101>;
				clock-names = "ipg", "ahb", "per";
				fsl,tuning-start-tap = <0x14>;
				fsl,tuning-step = <0x02>;
				bus-width = <0x04>;
				status = "disabled";
				assigned-clocks = <0x02 0x88>;
				assigned-clock-rates = <0x17d78400>;
				pinctrl-names = "default", "state_100mhz", "state_200mhz";
				pinctrl-0 = <0x32>;
				pinctrl-1 = <0x33>;
				pinctrl-2 = <0x34>;
				non-removable;
				phandle = <0xd6>;
			};

			mmc@30b50000 {
				compatible = "fsl,imx8mp-usdhc", "fsl,imx8mm-usdhc", "fsl,imx7d-usdhc";
				reg = <0x30b50000 0x10000>;
				interrupts = <0x00 0x17 0x04>;
				clocks = <0x02 0x00 0x02 0x5f 0x02 0x102>;
				clock-names = "ipg", "ahb", "per";
				fsl,tuning-start-tap = <0x14>;
				fsl,tuning-step = <0x02>;
				bus-width = <0x04>;
				status = "disabled";
				assigned-clocks = <0x02 0x89>;
				assigned-clock-rates = <0x17d78400>;
				pinctrl-names = "default", "state_100mhz", "state_200mhz";
				pinctrl-0 = <0x35>;
				pinctrl-1 = <0x36>;
				pinctrl-2 = <0x37>;
				phandle = <0xd7>;
			};

			mmc@30b60000 {
				compatible = "fsl,imx8mp-usdhc", "fsl,imx8mm-usdhc", "fsl,imx7d-usdhc";
				reg = <0x30b60000 0x10000>;
				interrupts = <0x00 0x18 0x04>;
				clocks = <0x02 0x00 0x02 0x5f 0x02 0x115>;
				clock-names = "ipg", "ahb", "per";
				fsl,tuning-start-tap = <0x14>;
				fsl,tuning-step = <0x02>;
				bus-width = <0x08>;
				status = "okay";
				assigned-clocks = <0x02 0xa9>;
				assigned-clock-rates = <0x17d78400>;
				pinctrl-names = "default", "state_100mhz", "state_200mhz";
				pinctrl-0 = <0x38>;
				pinctrl-1 = <0x39>;
				pinctrl-2 = <0x3a>;
				non-removable;
				phandle = <0xd8>;
			};

			spi@30bb0000 {
				compatible = "nxp,imx8mp-fspi";
				reg = <0x30bb0000 0x10000 0x8000000 0x10000000>;
				reg-names = "fspi_base", "fspi_mmap";
				interrupts = <0x00 0x6b 0x04>;
				clocks = <0x02 0xe2 0x02 0xe2>;
				clock-names = "fspi_en", "fspi";
				assigned-clock-rates = <0x4c4b400>;
				assigned-clocks = <0x02 0x87>;
				#address-cells = <0x01>;
				#size-cells = <0x00>;
				status = "okay";
				pinctrl-names = "default";
				pinctrl-0 = <0x3b>;
				phandle = <0xd9>;

				mt25qu256aba@0 {
					reg = <0x00>;
					#address-cells = <0x01>;
					#size-cells = <0x01>;
					compatible = "jedec,spi-nor";
					spi-max-frequency = <0x4c4b400>;
					spi-tx-bus-width = <0x04>;
					spi-rx-bus-width = <0x04>;
					phandle = <0xda>;
				};
			};

			dma-controller@30bd0000 {
				compatible = "fsl,imx8mq-sdma";
				reg = <0x30bd0000 0x10000>;
				interrupts = <0x00 0x02 0x04>;
				clocks = <0x02 0xec 0x02 0x6b>;
				clock-names = "ipg", "ahb";
				#dma-cells = <0x03>;
				fsl,sdma-ram-script-name = "imx/sdma/sdma-imx7d.bin";
				phandle = <0x1f>;
			};

			ethernet@30be0000 {
				compatible = "fsl,imx8mp-fec", "fsl,imx8mq-fec", "fsl,imx6sx-fec";
				reg = <0x30be0000 0x10000>;
				interrupts = <0x00 0x76 0x04 0x00 0x77 0x04 0x00 0x78 0x04 0x00 0x79 0x04>;
				clocks = <0x02 0xc0 0x02 0xf2 0x02 0x84 0x02 0x83 0x02 0x85>;
				clock-names = "ipg", "ahb", "ptp", "enet_clk_ref", "enet_out";
				assigned-clocks = <0x02 0x5e 0x02 0x84 0x02 0x83 0x02 0x85>;
				assigned-clock-parents = <0x02 0x36 0x02 0x3a 0x02 0x3b 0x02 0x39>;
				assigned-clock-rates = <0x00 0x5f5e100 0x7735940 0x00>;
				fsl,num-tx-queues = <0x03>;
				fsl,num-rx-queues = <0x03>;
				nvmem-cells = <0x3c>;
				nvmem-cell-names = "mac-address";
				fsl,stop-mode = <0x26 0x10 0x03>;
				status = "okay";
				pinctrl-names = "default";
				pinctrl-0 = <0x3d 0x3e>;
				phy-mode = "rgmii-id";
				phy-handle = <0x3f>;
				fsl,magic-packet;
				phandle = <0xdb>;

				mdio {
					#address-cells = <0x01>;
					#size-cells = <0x00>;

					fec-phy@0 {
						compatible = "ethernet-phy-ieee802.3-c22";
						reg = <0x00>;
						reset-gpios = <0x40 0x18 0x01>;
						reset-assert-us = <0x2710>;
						reset-deassert-us = <0x13880>;
						eee-broken-1000t;
						realtek,clkout-disable;
						phandle = <0x3f>;
					};
				};
			};

			ethernet@30bf0000 {
				compatible = "nxp,imx8mp-dwmac-eqos", "snps,dwmac-5.10a";
				reg = <0x30bf0000 0x10000>;
				interrupts = <0x00 0x87 0x04 0x00 0x86 0x04>;
				interrupt-names = "macirq", "eth_wake_irq";
				clocks = <0x02 0xed 0x02 0xe1 0x02 0x82 0x02 0x81>;
				clock-names = "stmmaceth", "pclk", "ptp_ref", "tx";
				assigned-clocks = <0x02 0x5e 0x02 0x82 0x02 0x81>;
				assigned-clock-parents = <0x02 0x36 0x02 0x3a 0x02 0x3b>;
				assigned-clock-rates = <0x00 0x5f5e100 0x7735940>;
				nvmem-cells = <0x41>;
				nvmem-cell-names = "mac-address";
				intf_mode = <0x26 0x04>;
				status = "okay";
				pinctrl-names = "default";
				pinctrl-0 = <0x42 0x43>;
				phy-mode = "rgmii-id";
				phy-handle = <0x44>;
				snps,force_thresh_dma_mode;
				snps,mtl-tx-config = <0x45>;
				snps,mtl-rx-config = <0x46>;
				phandle = <0xdc>;

				mdio {
					compatible = "snps,dwmac-mdio";
					#address-cells = <0x01>;
					#size-cells = <0x00>;

					eqos-phy@0 {
						compatible = "ethernet-phy-ieee802.3-c22";
						reset-gpios = <0x2b 0x0a 0x01>;
						reset-assert-us = <0x2710>;
						reset-deassert-us = <0x13880>;
						reg = <0x00>;
						eee-broken-1000t;
						realtek,clkout-disable;
						phandle = <0x44>;
					};
				};

				tx-queues-config {
					snps,tx-queues-to-use = <0x05>;
					snps,tx-sched-sp;
					phandle = <0x45>;

					queue0 {
						snps,dcb-algorithm;
						snps,priority = <0x01>;
					};

					queue1 {
						snps,dcb-algorithm;
						snps,priority = <0x02>;
					};

					queue2 {
						snps,dcb-algorithm;
						snps,priority = <0x04>;
					};

					queue3 {
						snps,dcb-algorithm;
						snps,priority = <0x08>;
					};

					queue4 {
						snps,dcb-algorithm;
						snps,priority = <0xf0>;
					};
				};

				rx-queues-config {
					snps,rx-queues-to-use = <0x05>;
					snps,rx-sched-sp;
					phandle = <0x46>;

					queue0 {
						snps,dcb-algorithm;
						snps,priority = <0x01>;
						snps,map-to-dma-channel = <0x00>;
					};

					queue1 {
						snps,dcb-algorithm;
						snps,priority = <0x02>;
						snps,map-to-dma-channel = <0x01>;
					};

					queue2 {
						snps,dcb-algorithm;
						snps,priority = <0x04>;
						snps,map-to-dma-channel = <0x02>;
					};

					queue3 {
						snps,dcb-algorithm;
						snps,priority = <0x08>;
						snps,map-to-dma-channel = <0x03>;
					};

					queue4 {
						snps,dcb-algorithm;
						snps,priority = <0xf0>;
						snps,map-to-dma-channel = <0x04>;
					};
				};
			};
		};

		interconnect@32700000 {
			compatible = "fsl,imx8mp-noc", "fsl,imx8m-noc", "syscon";
			reg = <0x32700000 0x100000>;
			phandle = <0xdd>;
		};

		bus@32c00000 {
			compatible = "fsl,aips-bus", "simple-bus";
			reg = <0x32c00000 0x400000>;
			#address-cells = <0x01>;
			#size-cells = <0x01>;
			ranges;
			phandle = <0xde>;

			mipi_dsi@32e60000 {
				#address-cells = <0x01>;
				#size-cells = <0x00>;
				compatible = "fsl,imx8mp-mipi-dsim";
				reg = <0x32e60000 0x10000>;
				clocks = <0x02 0x10d 0x02 0xab 0x02 0x10d>;
				clock-names = "cfg", "pll-ref", "apb-root";
				assigned-clocks = <0x02 0xab>;
				assigned-clock-parents = <0x02 0x02>;
				assigned-clock-rates = <0xb71b00>;
				interrupts = <0x00 0x12 0x04>;
				power-domains = <0x47 0x00>;
				status = "disabled";
				phandle = <0xdf>;

				port@0 {

					endpoint {
						remote-endpoint = <0x48>;
						phandle = <0x49>;
					};
				};
			};

			lcd-controller@32e80000 {
				#address-cells = <0x01>;
				#size-cells = <0x00>;
				compatible = "fsl,imx8mp-lcdif1";
				reg = <0x32e80000 0x10000>;
				clocks = <0x02 0x111 0x02 0x10e 0x02 0x10d>;
				clock-names = "pix", "disp-axi", "disp-apb";
				assigned-clocks = <0x02 0xac 0x02 0x61 0x02 0x62>;
				assigned-clock-parents = <0x02 0x28 0x02 0x41 0x02 0x38>;
				assigned-clock-rates = <0x00 0x1dcd6500 0xbebc200>;
				interrupts = <0x00 0x05 0x04>;
				blk-ctl = <0x47>;
				power-domains = <0x47 0x02>;
				status = "disabled";
				phandle = <0xe0>;

				port@0 {
					reg = <0x00>;
					phandle = <0x08>;

					endpoint {
						remote-endpoint = <0x49>;
						phandle = <0x48>;
					};
				};
			};

			lcd-controller@32e90000 {
				#address-cells = <0x01>;
				#size-cells = <0x00>;
				compatible = "fsl,imx8mp-lcdif2";
				reg = <0x32e90000 0x10000>;
				clocks = <0x02 0x112 0x02 0x10e 0x02 0x10d>;
				clock-names = "pix", "disp-axi", "disp-apb";
				assigned-clocks = <0x02 0x139 0x02 0x61 0x02 0x62>;
				assigned-clock-parents = <0x02 0x28 0x02 0x41 0x02 0x38>;
				assigned-clock-rates = <0x00 0x1dcd6500 0xbebc200>;
				interrupts = <0x00 0x06 0x04>;
				power-domains = <0x47 0x05>;
				status = "disabled";
				phandle = <0xe1>;

				port@0 {
					#address-cells = <0x01>;
					#size-cells = <0x00>;
					reg = <0x00>;
					phandle = <0x09>;

					endpoint@0 {
						reg = <0x00>;
						remote-endpoint = <0x4a>;
						phandle = <0x59>;
					};

					endpoint@1 {
						reg = <0x01>;
						remote-endpoint = <0x4b>;
						phandle = <0x5b>;
					};
				};
			};

			blk-ctrl@32ec0000 {
				compatible = "fsl,imx8mp-media-blk-ctrl", "syscon";
				reg = <0x32ec0000 0x10000>;
				power-domains = <0x4c 0x4d 0x4d 0x4c 0x4c 0x4e 0x4c 0x4f 0x4f 0x4e>;
				power-domain-names = "bus", "mipi-dsi1", "mipi-csi1", "lcdif1", "isi", "mipi-csi2", "lcdif2", "isp", "dwe", "mipi-dsi2";
				clocks = <0x02 0x10d 0x02 0x10e 0x02 0x10f 0x02 0x110 0x02 0x111 0x02 0x112 0x02 0x114 0x02 0x113>;
				clock-names = "apb", "axi", "cam1", "cam2", "disp1", "disp2", "isp", "phy";
				assigned-clocks = <0x02 0x61 0x02 0x62>;
				assigned-clock-parents = <0x02 0x41 0x02 0x38>;
				assigned-clock-rates = <0x1dcd6500 0xbebc200>;
				#power-domain-cells = <0x01>;
				phandle = <0x47>;
			};

			pcie-phy@32f00000 {
				compatible = "fsl,imx8mp-pcie-phy";
				reg = <0x32f00000 0x10000>;
				resets = <0x50 0x18 0x50 0x19>;
				reset-names = "pciephy", "perst";
				power-domains = <0x51 0x04>;
				#phy-cells = <0x00>;
				status = "okay";
				clocks = <0x02 0x10c>;
				clock-names = "ref";
				fsl,clkreq-unsupported;
				fsl,refclk-pad-mode = <0x02>;
				phandle = <0x68>;
			};

			blk-ctrl@32f10000 {
				compatible = "fsl,imx8mp-hsio-blk-ctrl", "syscon";
				reg = <0x32f10000 0x24>;
				clocks = <0x02 0xff 0x02 0xd9>;
				clock-names = "usb", "pcie";
				power-domains = <0x52 0x52 0x53 0x54 0x52 0x55>;
				power-domain-names = "bus", "usb", "usb-phy1", "usb-phy2", "pcie", "pcie-phy";
				#power-domain-cells = <0x01>;
				phandle = <0x51>;
			};

			blk-ctrl@32fc0000 {
				compatible = "fsl,imx8mp-hdmi-blk-ctrl", "syscon";
				reg = <0x32fc0000 0x23c>;
				clocks = <0x02 0x63 0x02 0x116 0x02 0xa8 0x02 0xa7>;
				clock-names = "apb", "axi", "ref_266m", "ref_24m";
				power-domains = <0x56 0x56 0x56 0x56 0x56 0x56 0x56 0x57 0x56 0x56>;
				power-domain-names = "bus", "irqsteer", "lcdif", "pai", "pvi", "trng", "hdmi-tx", "hdmi-tx-phy", "hrv", "hdcp";
				#power-domain-cells = <0x01>;
				status = "okay";
				phandle = <0x61>;
			};

			ldb@32ec005c {
				#address-cells = <0x01>;
				#size-cells = <0x00>;
				compatible = "fsl,imx8mp-ldb";
				clocks = <0x02 0x140>;
				clock-names = "ldb";
				assigned-clocks = <0x02 0xae>;
				assigned-clock-parents = <0x02 0x28>;
				gpr = <0x47>;
				power-domains = <0x4c>;
				status = "disabled";
				phandle = <0xe2>;

				lvds-channel@0 {
					#address-cells = <0x01>;
					#size-cells = <0x00>;
					reg = <0x00>;
					phys = <0x58>;
					phy-names = "ldb_phy";
					status = "disabled";

					port@0 {
						reg = <0x00>;

						endpoint {
							remote-endpoint = <0x59>;
							phandle = <0x4a>;
						};
					};
				};

				lvds-channel@1 {
					#address-cells = <0x01>;
					#size-cells = <0x00>;
					reg = <0x01>;
					phys = <0x5a>;
					phy-names = "ldb_phy";
					status = "disabled";

					port@0 {
						reg = <0x00>;

						endpoint {
							remote-endpoint = <0x5b>;
							phandle = <0x4b>;
						};
					};
				};
			};

			phy@32ec0128 {
				compatible = "fsl,imx8mp-lvds-phy";
				#address-cells = <0x01>;
				#size-cells = <0x00>;
				gpr = <0x47>;
				clocks = <0x02 0x10d>;
				clock-names = "apb";
				power-domains = <0x4c>;
				status = "disabled";
				phandle = <0xe3>;

				port@0 {
					reg = <0x00>;
					#phy-cells = <0x00>;
					phandle = <0x58>;
				};

				port@1 {
					reg = <0x01>;
					#phy-cells = <0x00>;
					phandle = <0x5a>;
				};
			};

			media_gpr@32ec0008 {
				compatible = "fsl,imx8mp-iomuxc-gpr", "syscon";
				reg = <0x32ec0008 0x04>;
				phandle = <0xe4>;
			};

			gasket@32ec0060 {
				compatible = "fsl,imx8mp-iomuxc-gpr", "syscon";
				reg = <0x32ec0060 0x28>;
				phandle = <0x5d>;
			};

			gasket@32ec0090 {
				compatible = "fsl,imx8mp-iomuxc-gpr", "syscon";
				reg = <0x32ec0090 0x28>;
				phandle = <0x5e>;
			};

			isi_chain@32e02000 {
				compatible = "fsl,imx8mp-iomuxc-gpr", "syscon";
				reg = <0x32e02000 0x04>;
				phandle = <0x5c>;
			};

			camera {
				compatible = "fsl,mxc-md", "simple-bus";
				#address-cells = <0x01>;
				#size-cells = <0x01>;
				ranges;
				status = "disabled";
				phandle = <0xe5>;

				isi@32e00000 {
					compatible = "fsl,imx8mp-isi", "fsl,imx8mn-isi";
					reg = <0x32e00000 0x2000>;
					interrupts = <0x00 0x10 0x04>;
					interface = <0x02 0x00 0x02>;
					clocks = <0x02 0x61 0x02 0x62 0x02 0x10e 0x02 0x10d>;
					clock-names = "disp_axi", "disp_apb", "disp_axi_root", "disp_apb_root";
					assigned-clocks = <0x02 0x10e 0x02 0x10d>;
					assigned-clock-rates = <0x1dcd6500 0xbebc200>;
					power-domains = <0x47 0x03>;
					isi_chain = <0x5c>;
					status = "disabled";
					fsl,chain_buf;
					phandle = <0xe6>;

					cap_device {
						compatible = "imx-isi-capture";
						status = "okay";
					};

					m2m_device {
						compatible = "imx-isi-m2m";
						status = "disabled";
					};
				};

				isi@32e02000 {
					compatible = "fsl,imx8mp-isi", "fsl,imx8mn-isi";
					reg = <0x32e02000 0x2000>;
					interrupts = <0x00 0x2a 0x04>;
					interface = <0x03 0x00 0x02>;
					clocks = <0x02 0x61 0x02 0x62 0x02 0x10e 0x02 0x10d>;
					clock-names = "disp_axi", "disp_apb", "disp_axi_root", "disp_apb_root";
					assigned-clocks = <0x02 0x10e 0x02 0x10d>;
					assigned-clock-rates = <0x1dcd6500 0xbebc200>;
					power-domains = <0x47 0x03>;
					status = "disabled";
					fsl,chain_buf;
					phandle = <0xe7>;

					cap_device {
						compatible = "imx-isi-capture";
						status = "okay";
					};
				};

				dwe@32e30000 {
					compatible = "fsl,imx8mp-dwe";
					clocks = <0x02 0x10e 0x02 0x10e 0x02 0x10d>;
					clock-names = "core", "axi", "ahb";
					reg = <0x32e30000 0x10000>;
					interrupts = <0x00 0x64 0x04>;
					power-domains = <0x47 0x07>;
					status = "disabled";
					phandle = <0xe8>;
				};

				isp@32e10000 {
					compatible = "fsl,imx8mp-isp";
					reg = <0x32e10000 0x10000>;
					interrupts = <0x00 0x4a 0x04>;
					clocks = <0x02 0x114 0x02 0x10e 0x02 0x10d 0x02 0x10f>;
					clock-names = "core", "axi", "ahb", "sensor";
					assigned-clocks = <0x02 0x138>;
					assigned-clock-parents = <0x02 0x40>;
					assigned-clock-rates = <0x1dcd6500>;
					power-domains = <0x47 0x01 0x47 0x06>;
					id = <0x00>;
					gpr = <0x47>;
					status = "disabled";
					phandle = <0xe9>;
				};

				isp@32e20000 {
					compatible = "fsl,imx8mp-isp";
					reg = <0x32e20000 0x10000>;
					interrupts = <0x00 0x4b 0x04>;
					clocks = <0x02 0x114 0x02 0x10e 0x02 0x10d 0x02 0x10f>;
					clock-names = "core", "axi", "ahb", "sensor";
					assigned-clocks = <0x02 0x138>;
					assigned-clock-parents = <0x02 0x40>;
					assigned-clock-rates = <0x1dcd6500>;
					power-domains = <0x47 0x01 0x47 0x06>;
					id = <0x01>;
					gpr = <0x47>;
					status = "disabled";
					phandle = <0xea>;
				};

				csi@32e40000 {
					compatible = "fsl,imx8mp-mipi-csi", "fsl,imx8mn-mipi-csi";
					reg = <0x32e40000 0x10000>;
					interrupts = <0x00 0x11 0x04>;
					clock-frequency = <0x1dcd6500>;
					clocks = <0x02 0x10f 0x02 0x61 0x02 0x10d>;
					clock-names = "mipi_clk", "disp_axi", "disp_apb";
					assigned-clocks = <0x02 0xaa>;
					assigned-clock-parents = <0x02 0x41>;
					assigned-clock-rates = <0x1dcd6500>;
					bus-width = <0x04>;
					csi-gpr = <0x5d>;
					gpr = <0x47>;
					power-domains = <0x47 0x01>;
					status = "disabled";
					#address-cells = <0x01>;
					#size-cells = <0x00>;
					phandle = <0xeb>;
				};

				csi@32e50000 {
					compatible = "fsl,imx8mp-mipi-csi", "fsl,imx8mn-mipi-csi";
					reg = <0x32e50000 0x10000>;
					interrupts = <0x00 0x50 0x04>;
					clock-frequency = <0xfdad680>;
					clocks = <0x02 0x110 0x02 0x61 0x02 0x10d>;
					clock-names = "mipi_clk", "disp_axi", "disp_apb";
					assigned-clocks = <0x02 0xad>;
					assigned-clock-parents = <0x02 0x41>;
					assigned-clock-rates = <0x1dcd6500>;
					bus-width = <0x04>;
					csi-gpr = <0x5e>;
					gpr = <0x47>;
					power-domains = <0x47 0x04>;
					status = "disabled";
					#address-cells = <0x01>;
					#size-cells = <0x00>;
					phandle = <0xec>;
				};
			};
		};

		bus@30c00000 {
			compatible = "fsl,aips-bus", "simple-bus";
			reg = <0x30c00000 0x400000>;
			#address-cells = <0x01>;
			#size-cells = <0x01>;
			ranges;
			phandle = <0xed>;

			spba-bus@30c00000 {
				compatible = "fsl,spba-bus", "simple-bus";
				reg = <0x30c00000 0x100000>;
				#address-cells = <0x01>;
				#size-cells = <0x01>;
				ranges;

				sai@30c10000 {
					compatible = "fsl,imx8mp-sai", "fsl,imx8mm-sai";
					reg = <0x30c10000 0x10000>;
					interrupts = <0x00 0x5f 0x04>;
					clocks = <0x2f 0x00 0x02 0x00 0x2f 0x01 0x02 0x00 0x02 0x00>;
					clock-names = "bus", "mclk0", "mclk1", "mclk2", "mclk3";
					dmas = <0x5f 0x00 0x02 0x00 0x5f 0x01 0x02 0x00>;
					dma-names = "rx", "tx";
					fsl,shared-interrupt;
					fsl,dataline = <0x00 0xff 0xff>;
					power-domains = <0x60>;
					status = "disabled";
					phandle = <0xee>;
				};

				sai@30c20000 {
					compatible = "fsl,imx8mp-sai", "fsl,imx8mm-sai";
					reg = <0x30c20000 0x10000>;
					interrupts = <0x00 0x60 0x04>;
					clocks = <0x2f 0x04 0x02 0x00 0x2f 0x05 0x02 0x00 0x02 0x00>;
					clock-names = "bus", "mclk0", "mclk1", "mclk2", "mclk3";
					dmas = <0x5f 0x02 0x02 0x00 0x5f 0x03 0x02 0x00>;
					dma-names = "rx", "tx";
					fsl,shared-interrupt;
					fsl,dataline = <0x00 0x0f 0x0f>;
					power-domains = <0x60>;
					status = "disabled";
					phandle = <0xef>;
				};

				sai@30c30000 {
					compatible = "fsl,imx8mp-sai", "fsl,imx8mm-sai";
					reg = <0x30c30000 0x10000>;
					interrupts = <0x00 0x32 0x04>;
					clocks = <0x2f 0x08 0x02 0x00 0x2f 0x09 0x02 0x00 0x02 0x00>;
					clock-names = "bus", "mclk0", "mclk1", "mclk2", "mclk3";
					dmas = <0x5f 0x04 0x02 0x00 0x5f 0x05 0x02 0x00>;
					dma-names = "rx", "tx";
					fsl,shared-interrupt;
					fsl,dataline = <0x00 0x03 0x03>;
					power-domains = <0x60>;
					status = "disabled";
					phandle = <0xf0>;
				};

				sai@30c50000 {
					compatible = "fsl,imx8mp-sai", "fsl,imx8mm-sai";
					reg = <0x30c50000 0x10000>;
					interrupts = <0x00 0x5a 0x04>;
					clocks = <0x2f 0x0c 0x02 0x00 0x2f 0x0d 0x02 0x00 0x02 0x00>;
					clock-names = "bus", "mclk0", "mclk1", "mclk2", "mclk3";
					dmas = <0x5f 0x08 0x02 0x00 0x5f 0x09 0x02 0x00>;
					dma-names = "rx", "tx";
					fsl,shared-interrupt;
					fsl,dataline = <0x00 0x0f 0x0f>;
					power-domains = <0x60>;
					status = "disabled";
					phandle = <0xf1>;
				};

				sai@30c60000 {
					compatible = "fsl,imx8mp-sai", "fsl,imx8mm-sai";
					reg = <0x30c60000 0x10000>;
					interrupts = <0x00 0x5a 0x04>;
					clocks = <0x2f 0x10 0x02 0x00 0x2f 0x11 0x02 0x00 0x02 0x00>;
					clock-names = "bus", "mclk0", "mclk1", "mclk2", "mclk3";
					dmas = <0x5f 0x0a 0x02 0x00 0x5f 0x0b 0x02 0x00>;
					dma-names = "rx", "tx";
					fsl,shared-interrupt;
					power-domains = <0x60>;
					status = "disabled";
					phandle = <0xf2>;
				};

				sai@30c80000 {
					compatible = "fsl,imx8mp-sai", "fsl,imx8mm-sai";
					reg = <0x30c80000 0x10000>;
					interrupts = <0x00 0x6f 0x04>;
					clocks = <0x2f 0x14 0x02 0x00 0x2f 0x15 0x02 0x00 0x02 0x00>;
					clock-names = "bus", "mclk0", "mclk1", "mclk2", "mclk3";
					dmas = <0x5f 0x0c 0x02 0x00 0x5f 0x0d 0x02 0x00>;
					dma-names = "rx", "tx";
					fsl,shared-interrupt;
					power-domains = <0x60>;
					status = "disabled";
					phandle = <0xf3>;
				};

				easrc@30c90000 {
					compatible = "fsl,imx8mn-easrc";
					reg = <0x30c90000 0x10000>;
					interrupts = <0x00 0x7a 0x04>;
					clocks = <0x2f 0x18>;
					clock-names = "mem";
					dmas = <0x5f 0x10 0x17 0x00 0x5f 0x11 0x17 0x00 0x5f 0x12 0x17 0x00 0x5f 0x13 0x17 0x00 0x5f 0x14 0x17 0x00 0x5f 0x15 0x17 0x00 0x5f 0x16 0x17 0x00 0x5f 0x17 0x17 0x00>;
					dma-names = "ctx0_rx", "ctx0_tx", "ctx1_rx", "ctx1_tx", "ctx2_rx", "ctx2_tx", "ctx3_rx", "ctx3_tx";
					firmware-name = "imx/easrc/easrc-imx8mn.bin";
					fsl,asrc-rate = <0xbb80>;
					fsl,asrc-format = <0x02>;
					power-domains = <0x60>;
					status = "okay";
					phandle = <0xf4>;
				};

				micfil@30ca0000 {
					compatible = "fsl,imx8mp-micfil";
					reg = <0x30ca0000 0x10000>;
					interrupts = <0x00 0x6d 0x04 0x00 0x6e 0x04 0x00 0x2c 0x04 0x00 0x2d 0x04>;
					clocks = <0x2f 0x19 0x2f 0x27 0x02 0x26 0x02 0x27 0x02 0x06>;
					clock-names = "ipg_clk", "ipg_clk_app", "pll8k", "pll11k", "clkext3";
					dmas = <0x5f 0x18 0x19 0x80000000>;
					dma-names = "rx";
					power-domains = <0x60>;
					status = "disabled";
					phandle = <0xf5>;
				};

				aud2htx@30cb0000 {
					compatible = "fsl,imx8mp-aud2htx";
					reg = <0x30cb0000 0x10000>;
					interrupts = <0x00 0x82 0x04>;
					clocks = <0x2f 0x21>;
					clock-names = "bus";
					dmas = <0x5f 0x1a 0x02 0x00>;
					dma-names = "tx";
					power-domains = <0x60>;
					status = "okay";
					phandle = <0x8c>;
				};

				xcvr@30cc0000 {
					compatible = "fsl,imx8mp-xcvr";
					reg = <0x30cc0000 0x800 0x30cc0800 0x400 0x30cc0c00 0x80 0x30cc0e00 0x80>;
					reg-names = "ram", "regs", "rxfifo", "txfifo";
					interrupts = <0x00 0x80 0x04 0x00 0x81 0x04 0x00 0x92 0x04>;
					clocks = <0x2f 0x1f 0x2f 0x26 0x2f 0x1c 0x2f 0x23>;
					clock-names = "ipg", "phy", "spba", "pll_ipg";
					dmas = <0x5f 0x1e 0x02 0x00 0x5f 0x1f 0x02 0x00>;
					dma-names = "rx", "tx";
					resets = <0x2f 0x00>;
					power-domains = <0x60>;
					status = "disabled";
					phandle = <0xf6>;
				};
			};

			dma-controller@30e00000 {
				compatible = "fsl,imx8mp-sdma", "fsl,imx7d-sdma";
				reg = <0x30e00000 0x10000>;
				interrupts = <0x00 0x22 0x04>;
				clocks = <0x2f 0x1b 0x2f 0x1b>;
				clock-names = "ipg", "ahb";
				#dma-cells = <0x03>;
				fsl,sdma-ram-script-name = "imx/sdma/sdma-imx7d.bin";
				fsl,ratio-1-1;
				power-domains = <0x60>;
				status = "disabled";
				phandle = <0xf7>;
			};

			dma-controller@30e10000 {
				compatible = "fsl,imx8mp-sdma", "fsl,imx7d-sdma";
				reg = <0x30e10000 0x10000>;
				interrupts = <0x00 0x67 0x04>;
				clocks = <0x02 0x141 0x02 0x141>;
				clock-names = "ipg", "ahb";
				#dma-cells = <0x03>;
				fsl,sdma-ram-script-name = "imx/sdma/sdma-imx7d.bin";
				fsl,ratio-1-1;
				power-domains = <0x60>;
				status = "okay";
				phandle = <0x5f>;
			};

			audio-blk-ctrl@30e20000 {
				compatible = "fsl,imx8mp-audio-blk-ctrl-legacy", "syscon";
				reg = <0x30e20000 0x50c>;
				power-domains = <0x60>;
				#clock-cells = <0x01>;
				#reset-cells = <0x01>;
				assigned-clocks = <0x2f 0x39>;
				assigned-clock-parents = <0x2f 0x38>;
				phandle = <0x2f>;
			};

			audiomix_dsp {
				compatible = "fsl,audiomix-dsp";
				power-domains = <0x60>;
				phandle = <0xf8>;
			};

			irqsteer@32fc2000 {
				compatible = "fsl,imx-irqsteer";
				reg = <0x32fc2000 0x1000>;
				interrupts = <0x00 0x2b 0x04>;
				interrupt-controller;
				#interrupt-cells = <0x01>;
				fsl,channel = <0x01>;
				fsl,num-irqs = <0x40>;
				clocks = <0x02 0x63>;
				clock-names = "ipg";
				assigned-clocks = <0x02 0x63>;
				assigned-clock-parents = <0x02 0x33>;
				assigned-clock-rates = <0x7ed6b40>;
				power-domains = <0x61 0x00>;
				status = "okay";
				phandle = <0x63>;
			};

			hdmi-pai-pvi@32fc4000 {
				compatible = "fsl,imx8mp-hdmi-pavi";
				reg = <0x32fc4000 0x1000>;
				clocks = <0x02 0x63>;
				power-domains = <0x61 0x03>;
				status = "okay";
				phandle = <0xf9>;
			};

			lcd-controller@32fc6000 {
				#address-cells = <0x01>;
				#size-cells = <0x00>;
				compatible = "fsl,imx8mp-lcdif1";
				reg = <0x32fc6000 0x10000>;
				clocks = <0x62 0x00 0x02 0x64 0x02 0x63>;
				clock-names = "pix", "disp-axi", "disp-apb";
				power-domains = <0x61 0x01>;
				assigned-clocks = <0x02 0x64 0x02 0x63>;
				assigned-clock-parents = <0x02 0x40 0x02 0x33>;
				assigned-clock-rates = <0x1dcd6500 0x7ed6b40>;
				interrupts = <0x08 0x04>;
				interrupt-parent = <0x63>;
				status = "okay";
				thres-low = <0x01 0x02>;
				thres-high = <0x03 0x04>;
				phandle = <0xfa>;

				port@0 {
					reg = <0x00>;
					phandle = <0x0a>;

					endpoint {
						remote-endpoint = <0x64>;
						phandle = <0x66>;
					};
				};
			};

			hdmi@32fd8000 {
				compatible = "fsl,imx8mp-hdmi";
				reg = <0x32fd8000 0x7eff>;
				interrupts = <0x00 0x04>;
				interrupt-parent = <0x63>;
				power-domains = <0x61 0x05>;
				clocks = <0x02 0x63 0x02 0xa7 0x62 0x00>;
				clock-names = "iahb", "isfr", "pix";
				assigned-clocks = <0x02 0x63 0x02 0x64 0x02 0xa7>;
				assigned-clock-parents = <0x02 0x33 0x02 0x40 0x02 0x02>;
				assigned-clock-rates = <0x7ed6b40 0x1dcd6500 0x16e3600>;
				status = "okay";
				pinctrl-names = "default";
				pinctrl-0 = <0x65>;
				phandle = <0xfb>;

				port@0 {

					endpoint {
						remote-endpoint = <0x66>;
						phandle = <0x64>;
					};
				};
			};

			hdmiphy@32fdff00 {
				compatible = "fsl,samsung-hdmi-phy";
				reg = <0x32fdff00 0x100>;
				clocks = <0x02 0x63 0x02 0xa7>;
				clock-names = "apb", "ref";
				assigned-clocks = <0x02 0xa7>;
				assigned-clock-parents = <0x02 0x02>;
				#clock-cells = <0x01>;
				clock-output-names = "hdmi_phy";
				#phy-cells = <0x00>;
				power-domains = <0x61 0x06>;
				status = "okay";
				phandle = <0x62>;
			};
		};

		dma-apbh@33000000 {
			compatible = "fsl,imx7d-dma-apbh", "fsl,imx28-dma-apbh";
			reg = <0x33000000 0x2000>;
			interrupts = <0x00 0x0c 0x04 0x00 0x0c 0x04 0x00 0x0c 0x04 0x00 0x0c 0x04>;
			interrupt-names = "gpmi0", "gpmi1", "gpmi2", "gpmi3";
			#dma-cells = <0x01>;
			dma-channels = <0x04>;
			clocks = <0x02 0xe4>;
			phandle = <0x67>;
		};

		gpmi-nand@33002000 {
			compatible = "fsl,imx7d-gpmi-nand";
			#address-cells = <0x01>;
			#size-cells = <0x01>;
			reg = <0x33002000 0x2000 0x33004000 0x4000>;
			reg-names = "gpmi-nand", "bch";
			interrupts = <0x00 0x0e 0x04>;
			interrupt-names = "bch";
			clocks = <0x02 0xe3 0x02 0xe4>;
			clock-names = "gpmi_io", "gpmi_bch_apb";
			dmas = <0x67 0x00>;
			dma-names = "rx-tx";
			status = "disabled";
			phandle = <0xfc>;
		};

		pcie@33800000 {
			compatible = "fsl,imx8mp-pcie";
			reg = <0x33800000 0x400000 0x1ff00000 0x80000>;
			reg-names = "dbi", "config";
			#address-cells = <0x03>;
			#size-cells = <0x02>;
			device_type = "pci";
			bus-range = <0x00 0xff>;
			ranges = <0x81000000 0x00 0x00 0x1ff80000 0x00 0x10000 0x82000000 0x00 0x18000000 0x18000000 0x00 0x7f00000>;
			num-lanes = <0x01>;
			num-viewport = <0x04>;
			interrupts = <0x00 0x8c 0x04>;
			interrupt-names = "msi";
			#interrupt-cells = <0x01>;
			interrupt-map-mask = <0x00 0x00 0x00 0x07>;
			interrupt-map = <0x00 0x00 0x00 0x01 0x01 0x00 0x7e 0x04 0x00 0x00 0x00 0x02 0x01 0x00 0x7d 0x04 0x00 0x00 0x00 0x03 0x01 0x00 0x7c 0x04 0x00 0x00 0x00 0x04 0x01 0x00 0x7b 0x04>;
			fsl,max-link-speed = <0x03>;
			linux,pci-domain = <0x00>;
			power-domains = <0x51 0x03>;
			resets = <0x50 0x1a 0x50 0x1b>;
			reset-names = "apps", "turnoff";
			phys = <0x68>;
			phy-names = "pcie-phy";
			status = "okay";
			clocks = <0x02 0x10c 0x02 0xd9 0x02 0x137>;
			clock-names = "pcie", "pcie_aux", "pcie_bus";
			assigned-clocks = <0x02 0x78>;
			assigned-clock-rates = <0x989680>;
			assigned-clock-parents = <0x02 0x39>;
			pinctrl-names = "default";
			pinctrl-0 = <0x69>;
			reset-gpio = <0x22 0x02 0x01>;
			phandle = <0xfd>;
		};

		pcie_ep@33800000 {
			compatible = "fsl,imx8mp-pcie-ep";
			reg = <0x33800000 0x400000 0x18000000 0x8000000>;
			reg-names = "regs", "addr_space";
			num-lanes = <0x01>;
			interrupts = <0x00 0x7f 0x04>;
			interrupt-names = "dma";
			fsl,max-link-speed = <0x03>;
			power-domains = <0x51 0x03>;
			resets = <0x50 0x1a 0x50 0x1b>;
			reset-names = "apps", "turnoff";
			phys = <0x68>;
			phy-names = "pcie-phy";
			num-ib-windows = <0x04>;
			num-ob-windows = <0x04>;
			status = "disabled";
			phandle = <0xfe>;
		};

		interrupt-controller@38800000 {
			compatible = "arm,gic-v3";
			reg = <0x38800000 0x10000 0x38880000 0xc0000>;
			#interrupt-cells = <0x03>;
			interrupt-controller;
			interrupts = <0x01 0x09 0x04>;
			interrupt-parent = <0x01>;
			phandle = <0x01>;
		};

		blk-ctl@38330000 {
			compatible = "fsl,imx8mp-vpu-blk-ctrl", "syscon";
			reg = <0x38330000 0x100>;
			#power-domain-cells = <0x01>;
			power-domains = <0x1e 0x6a 0x6b 0x6c>;
			power-domain-names = "bus", "g1", "g2", "h1";
			clocks = <0x02 0x106 0x02 0x10a 0x02 0x109>;
			clock-names = "g1", "g2", "h1";
			phandle = <0x70>;
		};

		memory-controller@3d400000 {
			compatible = "snps,ddrc-3.80a";
			reg = <0x3d400000 0x400000>;
			interrupts = <0x00 0x93 0x04>;
			phandle = <0xff>;
		};

		ddr-pmu@3d800000 {
			compatible = "fsl,imx8mp-ddr-pmu", "fsl,imx8m-ddr-pmu";
			reg = <0x3d800000 0x400000>;
			interrupts = <0x00 0x62 0x04>;
		};

		usb-phy@381f0040 {
			compatible = "fsl,imx8mp-usb-phy";
			reg = <0x381f0040 0x40>;
			clocks = <0x02 0x100>;
			clock-names = "phy";
			assigned-clocks = <0x02 0x93>;
			assigned-clock-parents = <0x02 0x02>;
			power-domains = <0x51 0x01>;
			#phy-cells = <0x00>;
			status = "okay";
			fsl,phy-tx-preemp-amp-tune = <0x03>;
			phandle = <0x6d>;
		};

		usb@32f10100 {
			compatible = "fsl,imx8mp-dwc3";
			reg = <0x32f10100 0x08 0x381f0000 0x20>;
			clocks = <0x02 0x10c 0x02 0x14a>;
			clock-names = "hsio", "suspend";
			interrupts = <0x00 0x94 0x04>;
			power-domains = <0x51 0x00>;
			#address-cells = <0x01>;
			#size-cells = <0x01>;
			dma-ranges = <0x40000000 0x40000000 0xc0000000>;
			ranges;
			status = "okay";
			phandle = <0x100>;

			usb@38100000 {
				compatible = "snps,dwc3";
				reg = <0x38100000 0x10000>;
				clocks = <0x02 0xff 0x02 0x92 0x02 0x14a>;
				clock-names = "bus_early", "ref", "suspend";
				interrupts = <0x00 0x28 0x04>;
				phys = <0x6d 0x6d>;
				phy-names = "usb2-phy", "usb3-phy";
				snps,gfladj-refclk-lpm-sel-quirk;
				snps,parkmode-disable-ss-quirk;
				dr_mode = "host";
				status = "okay";
				phandle = <0x101>;
			};
		};

		usb-phy@382f0040 {
			compatible = "fsl,imx8mp-usb-phy";
			reg = <0x382f0040 0x40>;
			clocks = <0x02 0x100>;
			clock-names = "phy";
			assigned-clocks = <0x02 0x93>;
			assigned-clock-parents = <0x02 0x02>;
			power-domains = <0x51 0x02>;
			#phy-cells = <0x00>;
			status = "okay";
			fsl,phy-tx-preemp-amp-tune = <0x03>;
			fsl,phy-tx-vref-tune = <0x0b>;
			phandle = <0x6e>;
		};

		usb@32f10108 {
			compatible = "fsl,imx8mp-dwc3";
			reg = <0x32f10108 0x08 0x382f0000 0x20>;
			clocks = <0x02 0x10c 0x02 0x14a>;
			clock-names = "hsio", "suspend";
			interrupts = <0x00 0x95 0x04>;
			power-domains = <0x51 0x00>;
			#address-cells = <0x01>;
			#size-cells = <0x01>;
			dma-ranges = <0x40000000 0x40000000 0xc0000000>;
			ranges;
			status = "okay";
			phandle = <0x102>;

			usb@38200000 {
				compatible = "snps,dwc3";
				reg = <0x38200000 0x10000>;
				clocks = <0x02 0xff 0x02 0x92 0x02 0x14a>;
				clock-names = "bus_early", "ref", "suspend";
				interrupts = <0x00 0x29 0x04>;
				phys = <0x6e 0x6e>;
				phy-names = "usb2-phy", "usb3-phy";
				snps,gfladj-refclk-lpm-sel-quirk;
				snps,parkmode-disable-ss-quirk;
				dr_mode = "host";
				status = "okay";
				pinctrl-names = "default";
				pinctrl-0 = <0x6f>;
				phandle = <0x103>;
			};
		};
	};

	vpu_g1@38300000 {
		compatible = "nxp,imx8mm-hantro", "nxp,imx8mp-hantro";
		reg = <0x00 0x38300000 0x00 0x100000>;
		reg-names = "regs_hantro";
		interrupts = <0x00 0x07 0x04>;
		interrupt-names = "irq_hantro";
		clocks = <0x02 0x106 0x02 0x11a>;
		clock-names = "clk_hantro", "clk_hantro_bus";
		assigned-clocks = <0x02 0x72 0x02 0x60>;
		assigned-clock-parents = <0x02 0x38 0x02 0x38>;
		assigned-clock-rates = <0x2faf0800 0x2faf0800>;
		power-domains = <0x70 0x00>;
		status = "okay";
		phandle = <0x104>;
	};

	vpu_g2@38310000 {
		compatible = "nxp,imx8mm-hantro", "nxp,imx8mp-hantro";
		reg = <0x00 0x38310000 0x00 0x100000>;
		reg-names = "regs_hantro";
		interrupts = <0x00 0x08 0x04>;
		interrupt-names = "irq_hantro";
		clocks = <0x02 0x10a 0x02 0x11a>;
		clock-names = "clk_hantro", "clk_hantro_bus";
		assigned-clocks = <0x02 0x73 0x02 0x60 0x02 0x17>;
		assigned-clock-parents = <0x02 0x2b 0x02 0x38>;
		assigned-clock-rates = <0x29b92700 0x2faf0800 0x29b92700>;
		power-domains = <0x70 0x01>;
		status = "okay";
		phandle = <0x105>;
	};

	vpu_vc8000e@38320000 {
		compatible = "nxp,imx8mp-hantro-vc8000e";
		reg = <0x00 0x38320000 0x00 0x10000>;
		reg-names = "regs_hantro_vc8000e";
		interrupts = <0x00 0x1e 0x04>;
		interrupt-names = "irq_hantro_vc8000e";
		clocks = <0x02 0x109 0x02 0x11a>;
		clock-names = "clk_hantro_vc8000e", "clk_hantro_vc8000e_bus";
		assigned-clocks = <0x02 0xb5 0x02 0x60>;
		assigned-clock-parents = <0x02 0x41 0x02 0x38>;
		assigned-clock-rates = <0x1dcd6500 0x2faf0800>;
		power-domains = <0x70 0x02>;
		status = "okay";
		phandle = <0x106>;
	};

	vpu_v4l2 {
		compatible = "nxp,imx8m-vsiv4l2";
		status = "okay";
		phandle = <0x107>;
	};

	gpu3d@38000000 {
		compatible = "fsl,imx8-gpu";
		reg = <0x00 0x38000000 0x00 0x8000>;
		interrupts = <0x00 0x03 0x04>;
		clocks = <0x02 0xf8 0x02 0x134 0x02 0x65 0x02 0x66>;
		clock-names = "core", "shader", "axi", "ahb";
		assigned-clocks = <0x02 0x133 0x02 0x134 0x02 0x65 0x02 0x66>;
		assigned-clock-parents = <0x02 0x41 0x02 0x41 0x02 0x38 0x02 0x38>;
		assigned-clock-rates = <0x3b9aca00 0x3b9aca00 0x2faf0800 0x17d78400>;
		power-domains = <0x71>;
		status = "okay";
		phandle = <0x74>;
	};

	gpu2d@38008000 {
		compatible = "fsl,imx8-gpu";
		reg = <0x00 0x38008000 0x00 0x8000>;
		interrupts = <0x00 0x19 0x04>;
		clocks = <0x02 0xf7 0x02 0x65 0x02 0x66>;
		clock-names = "core", "axi", "ahb";
		assigned-clocks = <0x02 0x135 0x02 0x65 0x02 0x66>;
		assigned-clock-parents = <0x02 0x41 0x02 0x38 0x02 0x38>;
		assigned-clock-rates = <0x3b9aca00 0x2faf0800 0x17d78400>;
		power-domains = <0x72>;
		status = "okay";
		phandle = <0x76>;
	};

	vipsi@38500000 {
		compatible = "fsl,imx8-gpu", "fsl,imx8-vipsi";
		reg = <0x00 0x38500000 0x00 0x20000>;
		interrupts = <0x00 0x0d 0x04>;
		clocks = <0x02 0x10b 0x02 0x10b 0x02 0x69 0x02 0x6a>;
		clock-names = "core", "shader", "axi", "ahb";
		assigned-clocks = <0x02 0x132 0x02 0x69 0x02 0x6a>;
		assigned-clock-parents = <0x02 0x41 0x02 0x38 0x02 0x38>;
		assigned-clock-rates = <0x3b9aca00 0x2faf0800 0x17d78400>;
		power-domains = <0x73>;
		status = "okay";
		phandle = <0x75>;
	};

	mix_gpu_ml {
		compatible = "fsl,imx8mp-gpu", "fsl,imx8-gpu-ss";
		cores = <0x74 0x75 0x76>;
		reg = <0x00 0x40000000 0x00 0xc0000000 0x00 0x00 0x00 0x10000000>;
		reg-names = "phys_baseaddr", "contiguous_mem";
		memory-region = <0x77>;
		status = "okay";
		phandle = <0x108>;
	};

	dsp@3b6e8000 {
		compatible = "fsl,imx8mp-hifi4";
		reg = <0x00 0x3b6e8000 0x00 0x88000>;
		clocks = <0x2f 0x20 0x2f 0x1d 0x2f 0x1e>;
		clock-names = "ocram", "core", "debug";
		firmware-name = "imx/dsp/hifi4.bin";
		power-domains = <0x60>;
		mbox-names = "tx", "rx", "rxdb";
		mboxes = <0x78 0x00 0x00 0x78 0x01 0x00 0x78 0x03 0x00>;
		memory-region = <0x79 0x7a 0x7b 0x7c>;
		fsl,dsp-ctrl = <0x2f>;
		status = "okay";
		phandle = <0x109>;
	};

	i2c-rpbus-3 {
		compatible = "fsl,i2c-rpbus";
		status = "disabled";
		phandle = <0x10a>;
	};

	etm@28440000 {
		compatible = "arm,coresight-etm4x", "arm,primecell";
		reg = <0x00 0x28440000 0x00 0x10000>;
		arm,primecell-periphid = <0xbb95d>;
		cpu = <0x0d>;
		clocks = <0x02 0x5d>;
		clock-names = "apb_pclk";
		status = "disabled";
		phandle = <0x10b>;

		out-ports {

			port {

				endpoint {
					remote-endpoint = <0x7d>;
					phandle = <0x81>;
				};
			};
		};
	};

	etm@28540000 {
		compatible = "arm,coresight-etm4x", "arm,primecell";
		reg = <0x00 0x28540000 0x00 0x10000>;
		arm,primecell-periphid = <0xbb95d>;
		cpu = <0x0e>;
		clocks = <0x02 0x5d>;
		clock-names = "apb_pclk";
		status = "disabled";
		phandle = <0x10c>;

		out-ports {

			port {

				endpoint {
					remote-endpoint = <0x7e>;
					phandle = <0x82>;
				};
			};
		};
	};

	etm@28640000 {
		compatible = "arm,coresight-etm4x", "arm,primecell";
		reg = <0x00 0x28640000 0x00 0x10000>;
		arm,primecell-periphid = <0xbb95d>;
		cpu = <0x0f>;
		clocks = <0x02 0x5d>;
		clock-names = "apb_pclk";
		status = "disabled";
		phandle = <0x10d>;

		out-ports {

			port {

				endpoint {
					remote-endpoint = <0x7f>;
					phandle = <0x83>;
				};
			};
		};
	};

	etm@28740000 {
		compatible = "arm,coresight-etm4x", "arm,primecell";
		reg = <0x00 0x28740000 0x00 0x10000>;
		arm,primecell-periphid = <0xbb95d>;
		cpu = <0x10>;
		clocks = <0x02 0x5d>;
		clock-names = "apb_pclk";
		status = "disabled";
		phandle = <0x10e>;

		out-ports {

			port {

				endpoint {
					remote-endpoint = <0x80>;
					phandle = <0x84>;
				};
			};
		};
	};

	funnel {
		compatible = "arm,coresight-static-funnel";
		status = "disabled";
		phandle = <0x10f>;

		in-ports {
			#address-cells = <0x01>;
			#size-cells = <0x00>;

			port@0 {
				reg = <0x00>;

				endpoint {
					remote-endpoint = <0x81>;
					phandle = <0x7d>;
				};
			};

			port@1 {
				reg = <0x01>;

				endpoint {
					remote-endpoint = <0x82>;
					phandle = <0x7e>;
				};
			};

			port@2 {
				reg = <0x02>;

				endpoint {
					remote-endpoint = <0x83>;
					phandle = <0x7f>;
				};
			};

			port@3 {
				reg = <0x03>;

				endpoint {
					remote-endpoint = <0x84>;
					phandle = <0x80>;
				};
			};
		};

		out-ports {

			port {

				endpoint {
					remote-endpoint = <0x85>;
					phandle = <0x86>;
				};
			};
		};
	};

	funnel@28c03000 {
		compatible = "arm,coresight-dynamic-funnel", "arm,primecell";
		reg = <0x00 0x28c03000 0x00 0x1000>;
		clocks = <0x02 0x5d>;
		clock-names = "apb_pclk";
		status = "disabled";
		phandle = <0x110>;

		in-ports {
			#address-cells = <0x01>;
			#size-cells = <0x00>;

			port@0 {
				reg = <0x00>;

				endpoint {
					remote-endpoint = <0x86>;
					phandle = <0x85>;
				};
			};

			port@1 {
				reg = <0x01>;

				endpoint {
					phandle = <0x111>;
				};
			};

			port@2 {
				reg = <0x02>;

				endpoint {
					phandle = <0x112>;
				};
			};
		};

		out-ports {

			port {

				endpoint {
					remote-endpoint = <0x87>;
					phandle = <0x88>;
				};
			};
		};
	};

	etf@28c04000 {
		compatible = "arm,coresight-tmc", "arm,primecell";
		reg = <0x00 0x28c04000 0x00 0x1000>;
		clocks = <0x02 0x5d>;
		clock-names = "apb_pclk";
		status = "disabled";

		in-ports {

			port {

				endpoint {
					remote-endpoint = <0x88>;
					phandle = <0x87>;
				};
			};
		};

		out-ports {

			port {

				endpoint {
					remote-endpoint = <0x89>;
					phandle = <0x8a>;
				};
			};
		};
	};

	etr@28c06000 {
		compatible = "arm,coresight-tmc", "arm,primecell";
		reg = <0x00 0x28c06000 0x00 0x1000>;
		clocks = <0x02 0x5d>;
		clock-names = "apb_pclk";
		status = "disabled";

		in-ports {

			port {

				endpoint {
					remote-endpoint = <0x8a>;
					phandle = <0x89>;
				};
			};
		};
	};

	leds {
		compatible = "gpio-leds";
		pinctrl-names = "default";
		pinctrl-0 = <0x8b>;

		heartbeat-led {
			label = "Heartbeat";
			gpios = <0x2b 0x0c 0x01>;
			linux,default-trigger = "heartbeat";
		};
	};

	sound-hdmi {
		compatible = "fsl,imx-audio-hdmi";
		model = "audio-hdmi";
		audio-cpu = <0x8c>;
		hdmi-out;
		constraint-rate = <0xac44 0x15888 0x2b110 0x7d00 0xbb80 0x17700 0x2ee00>;
		status = "okay";
	};

	chosen {
		stdout-path = "/soc@0/bus@30800000/serial@30890000";
	};

	usb-hub-reset {
		compatible = "gpio-reset";
		pinctrl-names = "default";
		pinctrl-0 = <0x8d>;
		reset-gpios = <0x8e 0x0a 0x00>;
		#reset-cells = <0x00>;
		initially-in-reset;
		phandle = <0x113>;
	};

	usb2-vbus-en {
		compatible = "gpio-reset";
		pinctrl-names = "default";
		pinctrl-0 = <0x8f>;
		reset-gpios = <0x40 0x14 0x00>;
		#reset-cells = <0x00>;
		initially-in-reset;
		phandle = <0x114>;
	};

	user-leds {
		compatible = "gpio-leds";
		pinctrl-names = "default";
		pinctrl-0 = <0x90>;

		user-led-1-green {
			label = "Green_1";
			color = <0x02>;
			gpios = <0x8e 0x0c 0x00>;
			default-state = "off";
		};

		user-led-1-red {
			label = "Red_1";
			color = <0x01>;
			gpios = <0x22 0x05 0x00>;
			default-state = "off";
		};

		user-led-2-green {
			label = "Green_2";
			color = <0x02>;
			gpios = <0x40 0x1c 0x00>;
			default-state = "off";
		};

		user-led-2-red {
			label = "Red_2";
			color = <0x01>;
			gpios = <0x22 0x01 0x00>;
			default-state = "off";
		};
	};

	__symbols__ {
		cpu_pd_wait = "/cpus/idle-states/cpu-pd-wait";
		A53_0 = "/cpus/cpu@0";
		A53_1 = "/cpus/cpu@1";
		A53_2 = "/cpus/cpu@2";
		A53_3 = "/cpus/cpu@3";
		A53_L2 = "/cpus/l2-cache0";
		a53_opp_table = "/opp-table";
		resmem = "/reserved-memory";
		ocram = "/reserved-memory/ocram@900000";
		gpu_reserved = "/reserved-memory/gpu_reserved@100000000";
		dsp_reserved = "/reserved-memory/dsp@92400000";
		dsp_reserved_heap = "/reserved-memory/dsp_reserved_heap";
		dsp_vdev0vring0 = "/reserved-memory/vdev0vring0@942f0000";
		dsp_vdev0vring1 = "/reserved-memory/vdev0vring1@942f8000";
		dsp_vdev0buffer = "/reserved-memory/vdev0buffer@94300000";
		osc_32k = "/clock-osc-32k";
		osc_24m = "/clock-osc-24m";
		clk_ext1 = "/clock-ext1";
		clk_ext2 = "/clock-ext2";
		clk_ext3 = "/clock-ext3";
		clk_ext4 = "/clock-ext4";
		sai1_mclk = "/sai-mclk1";
		sai2_mclk = "/sai-mclk2";
		sai3_mclk = "/sai-mclk3";
		sai5_mclk = "/sai-mclk5";
		sai6_mclk = "/sai-mclk6";
		sai7_mclk = "/sai-mclk7";
		audiomix_pd = "/power-domains/audiomix-pd";
		cpu_alert0 = "/thermal-zones/cpu-thermal/trips/trip0";
		cpu_crit0 = "/thermal-zones/cpu-thermal/trips/trip1";
		soc_alert0 = "/thermal-zones/soc-thermal/trips/trip0";
		soc_crit0 = "/thermal-zones/soc-thermal/trips/trip1";
		clk_dummy = "/clock-dummy";
		soc = "/soc@0";
		caam_sm = "/soc@0/caam-sm@100000";
		aips1 = "/soc@0/bus@30000000";
		gpio1 = "/soc@0/bus@30000000/gpio@30200000";
		gpio2 = "/soc@0/bus@30000000/gpio@30210000";
		gpio3 = "/soc@0/bus@30000000/gpio@30220000";
		gpio4 = "/soc@0/bus@30000000/gpio@30230000";
		gpio5 = "/soc@0/bus@30000000/gpio@30240000";
		tmu = "/soc@0/bus@30000000/tmu@30260000";
		wdog1 = "/soc@0/bus@30000000/watchdog@30280000";
		wdog2 = "/soc@0/bus@30000000/watchdog@30290000";
		wdog3 = "/soc@0/bus@30000000/watchdog@302a0000";
		iomuxc = "/soc@0/bus@30000000/pinctrl@30330000";
		pinctrl_fec = "/soc@0/bus@30000000/pinctrl@30330000/fecgrp";
		pinctrl_ecspi2 = "/soc@0/bus@30000000/pinctrl@30330000/ecspi2grp";
		pinctrl_ecspi2_cs = "/soc@0/bus@30000000/pinctrl@30330000/ecspi2cs";
		pinctrl_eqos = "/soc@0/bus@30000000/pinctrl@30330000/eqosgrp";
		pinctrl_ecos_phy_reset = "/soc@0/bus@30000000/pinctrl@30330000/ecosphyrstgrp";
		pinctrl_flexspi0 = "/soc@0/bus@30000000/pinctrl@30330000/flexspi0grp";
		pinctrl_gpio_led = "/soc@0/bus@30000000/pinctrl@30330000/gpioledgrp";
		pinctrl_i2c1 = "/soc@0/bus@30000000/pinctrl@30330000/i2c1grp";
		pinctrl_i2c2 = "/soc@0/bus@30000000/pinctrl@30330000/i2c2grp";
		pinctrl_i2c3 = "/soc@0/bus@30000000/pinctrl@30330000/i2c3grp";
		pinctrl_i2c5 = "/soc@0/bus@30000000/pinctrl@30330000/i2c5grp";
		pinctrl_i2c6 = "/soc@0/bus@30000000/pinctrl@30330000/i2c6grp";
		pinctrl_pmic = "/soc@0/bus@30000000/pinctrl@30330000/pmicirq";
		pinctrl_pdm = "/soc@0/bus@30000000/pinctrl@30330000/pdmgrp";
		pinctrl_uart1 = "/soc@0/bus@30000000/pinctrl@30330000/uart1grp";
		pinctrl_uart2 = "/soc@0/bus@30000000/pinctrl@30330000/uart2grp";
		pinctrl_uart3 = "/soc@0/bus@30000000/pinctrl@30330000/uart3grp";
		pinctrl_uart4 = "/soc@0/bus@30000000/pinctrl@30330000/uart4grp";
		pinctrl_usdhc1 = "/soc@0/bus@30000000/pinctrl@30330000/usdhc1grp";
		pinctrl_usdhc1_100mhz = "/soc@0/bus@30000000/pinctrl@30330000/usdhc1grp-100mhz";
		pinctrl_usdhc1_200mhz = "/soc@0/bus@30000000/pinctrl@30330000/usdhc1grp-200mhz";
		pinctrl_usdhc2 = "/soc@0/bus@30000000/pinctrl@30330000/usdhc2grp";
		pinctrl_usdhc2_100mhz = "/soc@0/bus@30000000/pinctrl@30330000/usdhc2grp-100mhz";
		pinctrl_usdhc2_200mhz = "/soc@0/bus@30000000/pinctrl@30330000/usdhc2grp-200mhz";
		pinctrl_usdhc3 = "/soc@0/bus@30000000/pinctrl@30330000/usdhc3grp";
		pinctrl_usdhc3_100mhz = "/soc@0/bus@30000000/pinctrl@30330000/usdhc3grp-100mhz";
		pinctrl_usdhc3_200mhz = "/soc@0/bus@30000000/pinctrl@30330000/usdhc3grp-200mhz";
		pinctrl_wdog = "/soc@0/bus@30000000/pinctrl@30330000/wdoggrp";
		pinctrl_flexcan1 = "/soc@0/bus@30000000/pinctrl@30330000/flexcan1grp";
		pinctrl_flexcan2 = "/soc@0/bus@30000000/pinctrl@30330000/flexcan2grp";
		pinctrl_hdmi = "/soc@0/bus@30000000/pinctrl@30330000/hdmigrp";
		pinctrl_fec_phy_reset = "/soc@0/bus@30000000/pinctrl@30330000/fecphyrstgrp";
		pinctrl_ie_di4o4 = "/soc@0/bus@30000000/pinctrl@30330000/iedi4o4grp";
		pinctrl_pcie = "/soc@0/bus@30000000/pinctrl@30330000/pciegrp";
		pinctrl_usb_hub_reset = "/soc@0/bus@30000000/pinctrl@30330000/usbhubrst";
		pinctrl_usb_mux_sel = "/soc@0/bus@30000000/pinctrl@30330000/usbmuxselgrp";
		pinctrl_usb2_vbus_en = "/soc@0/bus@30000000/pinctrl@30330000/usb2vbusengrp";
		pinctrl_user_leds = "/soc@0/bus@30000000/pinctrl@30330000/userledsgrp";
		gpr = "/soc@0/bus@30000000/iomuxc-gpr@30340000";
		ocotp = "/soc@0/bus@30000000/efuse@30350000";
		imx8mp_uid = "/soc@0/bus@30000000/efuse@30350000/unique-id@8";
		cpu_speed_grade = "/soc@0/bus@30000000/efuse@30350000/speed-grade@10";
		eth_mac1 = "/soc@0/bus@30000000/efuse@30350000/mac-address@90";
		eth_mac2 = "/soc@0/bus@30000000/efuse@30350000/mac-address@96";
		imx8mp_soc = "/soc@0/bus@30000000/efuse@30350000/imx8mp-soc";
		anatop = "/soc@0/bus@30000000/anatop@30360000";
		irq_sec_vio = "/soc@0/bus@30000000/caam_secvio";
		caam_snvs = "/soc@0/bus@30000000/caam-snvs@30370000";
		snvs = "/soc@0/bus@30000000/snvs@30370000";
		snvs_rtc = "/soc@0/bus@30000000/snvs@30370000/snvs-rtc-lp";
		snvs_pwrkey = "/soc@0/bus@30000000/snvs@30370000/snvs-powerkey";
		snvs_lpgpr = "/soc@0/bus@30000000/snvs@30370000/snvs-lpgpr";
		clk = "/soc@0/bus@30000000/clock-controller@30380000";
		src = "/soc@0/bus@30000000/reset-controller@30390000";
		gpc = "/soc@0/bus@30000000/gpc@303a0000";
		pgc_mipi_phy1 = "/soc@0/bus@30000000/gpc@303a0000/pgc/power-domain@0";
		pgc_pcie_phy = "/soc@0/bus@30000000/gpc@303a0000/pgc/power-domain@1";
		pgc_usb1_phy = "/soc@0/bus@30000000/gpc@303a0000/pgc/power-domain@2";
		pgc_usb2_phy = "/soc@0/bus@30000000/gpc@303a0000/pgc/power-domain@3";
		pgc_gpumix = "/soc@0/bus@30000000/gpc@303a0000/pgc/power-domain@7";
		pgc_gpu2d = "/soc@0/bus@30000000/gpc@303a0000/pgc/power-domain@6";
		pgc_gpu3d = "/soc@0/bus@30000000/gpc@303a0000/pgc/power-domain@9";
		pgc_mediamix = "/soc@0/bus@30000000/gpc@303a0000/pgc/power-domain@10";
		pgc_hdmimix = "/soc@0/bus@30000000/gpc@303a0000/pgc/power-domains@14";
		pgc_hdmi_phy = "/soc@0/bus@30000000/gpc@303a0000/pgc/power-domains@15";
		pgc_mipi_phy2 = "/soc@0/bus@30000000/gpc@303a0000/pgc/power-domain@16";
		pgc_hsiomix = "/soc@0/bus@30000000/gpc@303a0000/pgc/power-domain@17";
		pgc_ispdwp = "/soc@0/bus@30000000/gpc@303a0000/pgc/power-domain@18";
		pgc_vpumix = "/soc@0/bus@30000000/gpc@303a0000/pgc/power-domain@19";
		pgc_vpu_g1 = "/soc@0/bus@30000000/gpc@303a0000/pgc/power-domain@20";
		pgc_vpu_g2 = "/soc@0/bus@30000000/gpc@303a0000/pgc/power-domain@21";
		pgc_vpu_vc8000e = "/soc@0/bus@30000000/gpc@303a0000/pgc/power-domain@22";
		pgc_mlmix = "/soc@0/bus@30000000/gpc@303a0000/pgc/power-domain@24";
		aips2 = "/soc@0/bus@30400000";
		pwm1 = "/soc@0/bus@30400000/pwm@30660000";
		pwm2 = "/soc@0/bus@30400000/pwm@30670000";
		pwm3 = "/soc@0/bus@30400000/pwm@30680000";
		pwm4 = "/soc@0/bus@30400000/pwm@30690000";
		system_counter = "/soc@0/bus@30400000/timer@306a0000";
		aips3 = "/soc@0/bus@30800000";
		ecspi1 = "/soc@0/bus@30800000/spi@30820000";
		ecspi2 = "/soc@0/bus@30800000/spi@30830000";
		spidev2_0 = "/soc@0/bus@30800000/spi@30830000/spidev2@0";
		ecspi3 = "/soc@0/bus@30800000/spi@30840000";
		uart1 = "/soc@0/bus@30800000/serial@30860000";
		uart3 = "/soc@0/bus@30800000/serial@30880000";
		uart2 = "/soc@0/bus@30800000/serial@30890000";
		flexcan1 = "/soc@0/bus@30800000/can@308c0000";
		flexcan2 = "/soc@0/bus@30800000/can@308d0000";
		crypto = "/soc@0/bus@30800000/crypto@30900000";
		sec_jr0 = "/soc@0/bus@30800000/crypto@30900000/jr@1000";
		sec_jr1 = "/soc@0/bus@30800000/crypto@30900000/jr@2000";
		sec_jr2 = "/soc@0/bus@30800000/crypto@30900000/jr@3000";
		i2c1 = "/soc@0/bus@30800000/i2c@30a20000";
		pmic = "/soc@0/bus@30800000/i2c@30a20000/pca9450@25";
		buck1 = "/soc@0/bus@30800000/i2c@30a20000/pca9450@25/regulators/BUCK1";
		buck2 = "/soc@0/bus@30800000/i2c@30a20000/pca9450@25/regulators/BUCK2";
		buck4 = "/soc@0/bus@30800000/i2c@30a20000/pca9450@25/regulators/BUCK4";
		buck5 = "/soc@0/bus@30800000/i2c@30a20000/pca9450@25/regulators/BUCK5";
		buck6 = "/soc@0/bus@30800000/i2c@30a20000/pca9450@25/regulators/BUCK6";
		ldo1 = "/soc@0/bus@30800000/i2c@30a20000/pca9450@25/regulators/LDO1";
		ldo2 = "/soc@0/bus@30800000/i2c@30a20000/pca9450@25/regulators/LDO2";
		ldo3 = "/soc@0/bus@30800000/i2c@30a20000/pca9450@25/regulators/LDO3";
		ldo4 = "/soc@0/bus@30800000/i2c@30a20000/pca9450@25/regulators/LDO4";
		ldo5 = "/soc@0/bus@30800000/i2c@30a20000/pca9450@25/regulators/LDO5";
		i2c2 = "/soc@0/bus@30800000/i2c@30a30000";
		ab1805_rtc = "/soc@0/bus@30800000/i2c@30a30000/rtc@69";
		i2c3 = "/soc@0/bus@30800000/i2c@30a40000";
		pca9555_sb = "/soc@0/bus@30800000/i2c@30a40000/pca9555-sb@21";
		i2c4 = "/soc@0/bus@30800000/i2c@30a50000";
		uart4 = "/soc@0/bus@30800000/serial@30a60000";
		mu = "/soc@0/bus@30800000/mailbox@30aa0000";
		mu2 = "/soc@0/bus@30800000/mailbox@30e60000";
		i2c5 = "/soc@0/bus@30800000/i2c@30ad0000";
		i2c6 = "/soc@0/bus@30800000/i2c@30ae0000";
		usdhc1 = "/soc@0/bus@30800000/mmc@30b40000";
		usdhc2 = "/soc@0/bus@30800000/mmc@30b50000";
		usdhc3 = "/soc@0/bus@30800000/mmc@30b60000";
		flexspi = "/soc@0/bus@30800000/spi@30bb0000";
		flash0 = "/soc@0/bus@30800000/spi@30bb0000/mt25qu256aba@0";
		sdma1 = "/soc@0/bus@30800000/dma-controller@30bd0000";
		fec = "/soc@0/bus@30800000/ethernet@30be0000";
		fecphy = "/soc@0/bus@30800000/ethernet@30be0000/mdio/fec-phy@0";
		eqos = "/soc@0/bus@30800000/ethernet@30bf0000";
		eqosphy = "/soc@0/bus@30800000/ethernet@30bf0000/mdio/eqos-phy@0";
		mtl_tx_setup = "/soc@0/bus@30800000/ethernet@30bf0000/tx-queues-config";
		mtl_rx_setup = "/soc@0/bus@30800000/ethernet@30bf0000/rx-queues-config";
		noc = "/soc@0/interconnect@32700000";
		aips4 = "/soc@0/bus@32c00000";
		mipi_dsi = "/soc@0/bus@32c00000/mipi_dsi@32e60000";
		dsim_from_lcdif = "/soc@0/bus@32c00000/mipi_dsi@32e60000/port@0/endpoint";
		lcdif1 = "/soc@0/bus@32c00000/lcd-controller@32e80000";
		lcdif1_disp = "/soc@0/bus@32c00000/lcd-controller@32e80000/port@0";
		lcdif_to_dsim = "/soc@0/bus@32c00000/lcd-controller@32e80000/port@0/endpoint";
		lcdif2 = "/soc@0/bus@32c00000/lcd-controller@32e90000";
		lcdif2_disp = "/soc@0/bus@32c00000/lcd-controller@32e90000/port@0";
		lcdif2_disp_ldb_ch0 = "/soc@0/bus@32c00000/lcd-controller@32e90000/port@0/endpoint@0";
		lcdif2_disp_ldb_ch1 = "/soc@0/bus@32c00000/lcd-controller@32e90000/port@0/endpoint@1";
		media_blk_ctrl = "/soc@0/bus@32c00000/blk-ctrl@32ec0000";
		pcie_phy = "/soc@0/bus@32c00000/pcie-phy@32f00000";
		hsio_blk_ctrl = "/soc@0/bus@32c00000/blk-ctrl@32f10000";
		hdmi_blk_ctrl = "/soc@0/bus@32c00000/blk-ctrl@32fc0000";
		ldb = "/soc@0/bus@32c00000/ldb@32ec005c";
		ldb_ch0 = "/soc@0/bus@32c00000/ldb@32ec005c/lvds-channel@0/port@0/endpoint";
		ldb_ch1 = "/soc@0/bus@32c00000/ldb@32ec005c/lvds-channel@1/port@0/endpoint";
		ldb_phy = "/soc@0/bus@32c00000/phy@32ec0128";
		ldb_phy1 = "/soc@0/bus@32c00000/phy@32ec0128/port@0";
		ldb_phy2 = "/soc@0/bus@32c00000/phy@32ec0128/port@1";
		mediamix_gpr = "/soc@0/bus@32c00000/media_gpr@32ec0008";
		mediamix_gasket0 = "/soc@0/bus@32c00000/gasket@32ec0060";
		mediamix_gasket1 = "/soc@0/bus@32c00000/gasket@32ec0090";
		isi_chain_buf = "/soc@0/bus@32c00000/isi_chain@32e02000";
		cameradev = "/soc@0/bus@32c00000/camera";
		isi_0 = "/soc@0/bus@32c00000/camera/isi@32e00000";
		isi_1 = "/soc@0/bus@32c00000/camera/isi@32e02000";
		dewarp = "/soc@0/bus@32c00000/camera/dwe@32e30000";
		isp_0 = "/soc@0/bus@32c00000/camera/isp@32e10000";
		isp_1 = "/soc@0/bus@32c00000/camera/isp@32e20000";
		mipi_csi_0 = "/soc@0/bus@32c00000/camera/csi@32e40000";
		mipi_csi_1 = "/soc@0/bus@32c00000/camera/csi@32e50000";
		aips5 = "/soc@0/bus@30c00000";
		sai1 = "/soc@0/bus@30c00000/spba-bus@30c00000/sai@30c10000";
		sai2 = "/soc@0/bus@30c00000/spba-bus@30c00000/sai@30c20000";
		sai3 = "/soc@0/bus@30c00000/spba-bus@30c00000/sai@30c30000";
		sai5 = "/soc@0/bus@30c00000/spba-bus@30c00000/sai@30c50000";
		sai6 = "/soc@0/bus@30c00000/spba-bus@30c00000/sai@30c60000";
		sai7 = "/soc@0/bus@30c00000/spba-bus@30c00000/sai@30c80000";
		easrc = "/soc@0/bus@30c00000/spba-bus@30c00000/easrc@30c90000";
		micfil = "/soc@0/bus@30c00000/spba-bus@30c00000/micfil@30ca0000";
		aud2htx = "/soc@0/bus@30c00000/spba-bus@30c00000/aud2htx@30cb0000";
		xcvr = "/soc@0/bus@30c00000/spba-bus@30c00000/xcvr@30cc0000";
		sdma3 = "/soc@0/bus@30c00000/dma-controller@30e00000";
		sdma2 = "/soc@0/bus@30c00000/dma-controller@30e10000";
		audio_blk_ctrl = "/soc@0/bus@30c00000/audio-blk-ctrl@30e20000";
		audiomix_dsp = "/soc@0/bus@30c00000/audiomix_dsp";
		irqsteer_hdmi = "/soc@0/bus@30c00000/irqsteer@32fc2000";
		hdmi_pavi = "/soc@0/bus@30c00000/hdmi-pai-pvi@32fc4000";
		lcdif3 = "/soc@0/bus@30c00000/lcd-controller@32fc6000";
		lcdif3_disp = "/soc@0/bus@30c00000/lcd-controller@32fc6000/port@0";
		lcdif3_to_hdmi = "/soc@0/bus@30c00000/lcd-controller@32fc6000/port@0/endpoint";
		hdmi = "/soc@0/bus@30c00000/hdmi@32fd8000";
		hdmi_from_lcdif3 = "/soc@0/bus@30c00000/hdmi@32fd8000/port@0/endpoint";
		hdmiphy = "/soc@0/bus@30c00000/hdmiphy@32fdff00";
		dma_apbh = "/soc@0/dma-apbh@33000000";
		gpmi = "/soc@0/gpmi-nand@33002000";
		pcie = "/soc@0/pcie@33800000";
		pcie_ep = "/soc@0/pcie_ep@33800000";
		gic = "/soc@0/interrupt-controller@38800000";
		vpumix_blk_ctl = "/soc@0/blk-ctl@38330000";
		edacmc = "/soc@0/memory-controller@3d400000";
		usb3_phy0 = "/soc@0/usb-phy@381f0040";
		usb3_0 = "/soc@0/usb@32f10100";
		usb_dwc3_0 = "/soc@0/usb@32f10100/usb@38100000";
		usb3_phy1 = "/soc@0/usb-phy@382f0040";
		usb3_1 = "/soc@0/usb@32f10108";
		usb_dwc3_1 = "/soc@0/usb@32f10108/usb@38200000";
		vpu_g1 = "/vpu_g1@38300000";
		vpu_g2 = "/vpu_g2@38310000";
		vpu_vc8000e = "/vpu_vc8000e@38320000";
		vpu_v4l2 = "/vpu_v4l2";
		gpu_3d = "/gpu3d@38000000";
		gpu_2d = "/gpu2d@38008000";
		ml_vipsi = "/vipsi@38500000";
		mix_gpu_ml = "/mix_gpu_ml";
		dsp = "/dsp@3b6e8000";
		i2c_rpbus_3 = "/i2c-rpbus-3";
		etm0 = "/etm@28440000";
		etm0_out_port = "/etm@28440000/out-ports/port/endpoint";
		etm1 = "/etm@28540000";
		etm1_out_port = "/etm@28540000/out-ports/port/endpoint";
		etm2 = "/etm@28640000";
		etm2_out_port = "/etm@28640000/out-ports/port/endpoint";
		etm3 = "/etm@28740000";
		etm3_out_port = "/etm@28740000/out-ports/port/endpoint";
		funnel0 = "/funnel";
		ca_funnel_in_port0 = "/funnel/in-ports/port@0/endpoint";
		ca_funnel_in_port1 = "/funnel/in-ports/port@1/endpoint";
		ca_funnel_in_port2 = "/funnel/in-ports/port@2/endpoint";
		ca_funnel_in_port3 = "/funnel/in-ports/port@3/endpoint";
		ca_funnel_out_port0 = "/funnel/out-ports/port/endpoint";
		funnel1 = "/funnel@28c03000";
		hugo_funnel_in_port0 = "/funnel@28c03000/in-ports/port@0/endpoint";
		hugo_funnel_in_port1 = "/funnel@28c03000/in-ports/port@1/endpoint";
		hugo_funnel_in_port2 = "/funnel@28c03000/in-ports/port@2/endpoint";
		hugo_funnel_out_port0 = "/funnel@28c03000/out-ports/port/endpoint";
		etf_in_port = "/etf@28c04000/in-ports/port/endpoint";
		etf_out_port = "/etf@28c04000/out-ports/port/endpoint";
		etr_in_port = "/etr@28c06000/in-ports/port/endpoint";
		usb_hub_reset = "/usb-hub-reset";
		usb2_vbus_en = "/usb2-vbus-en";
	};
};
